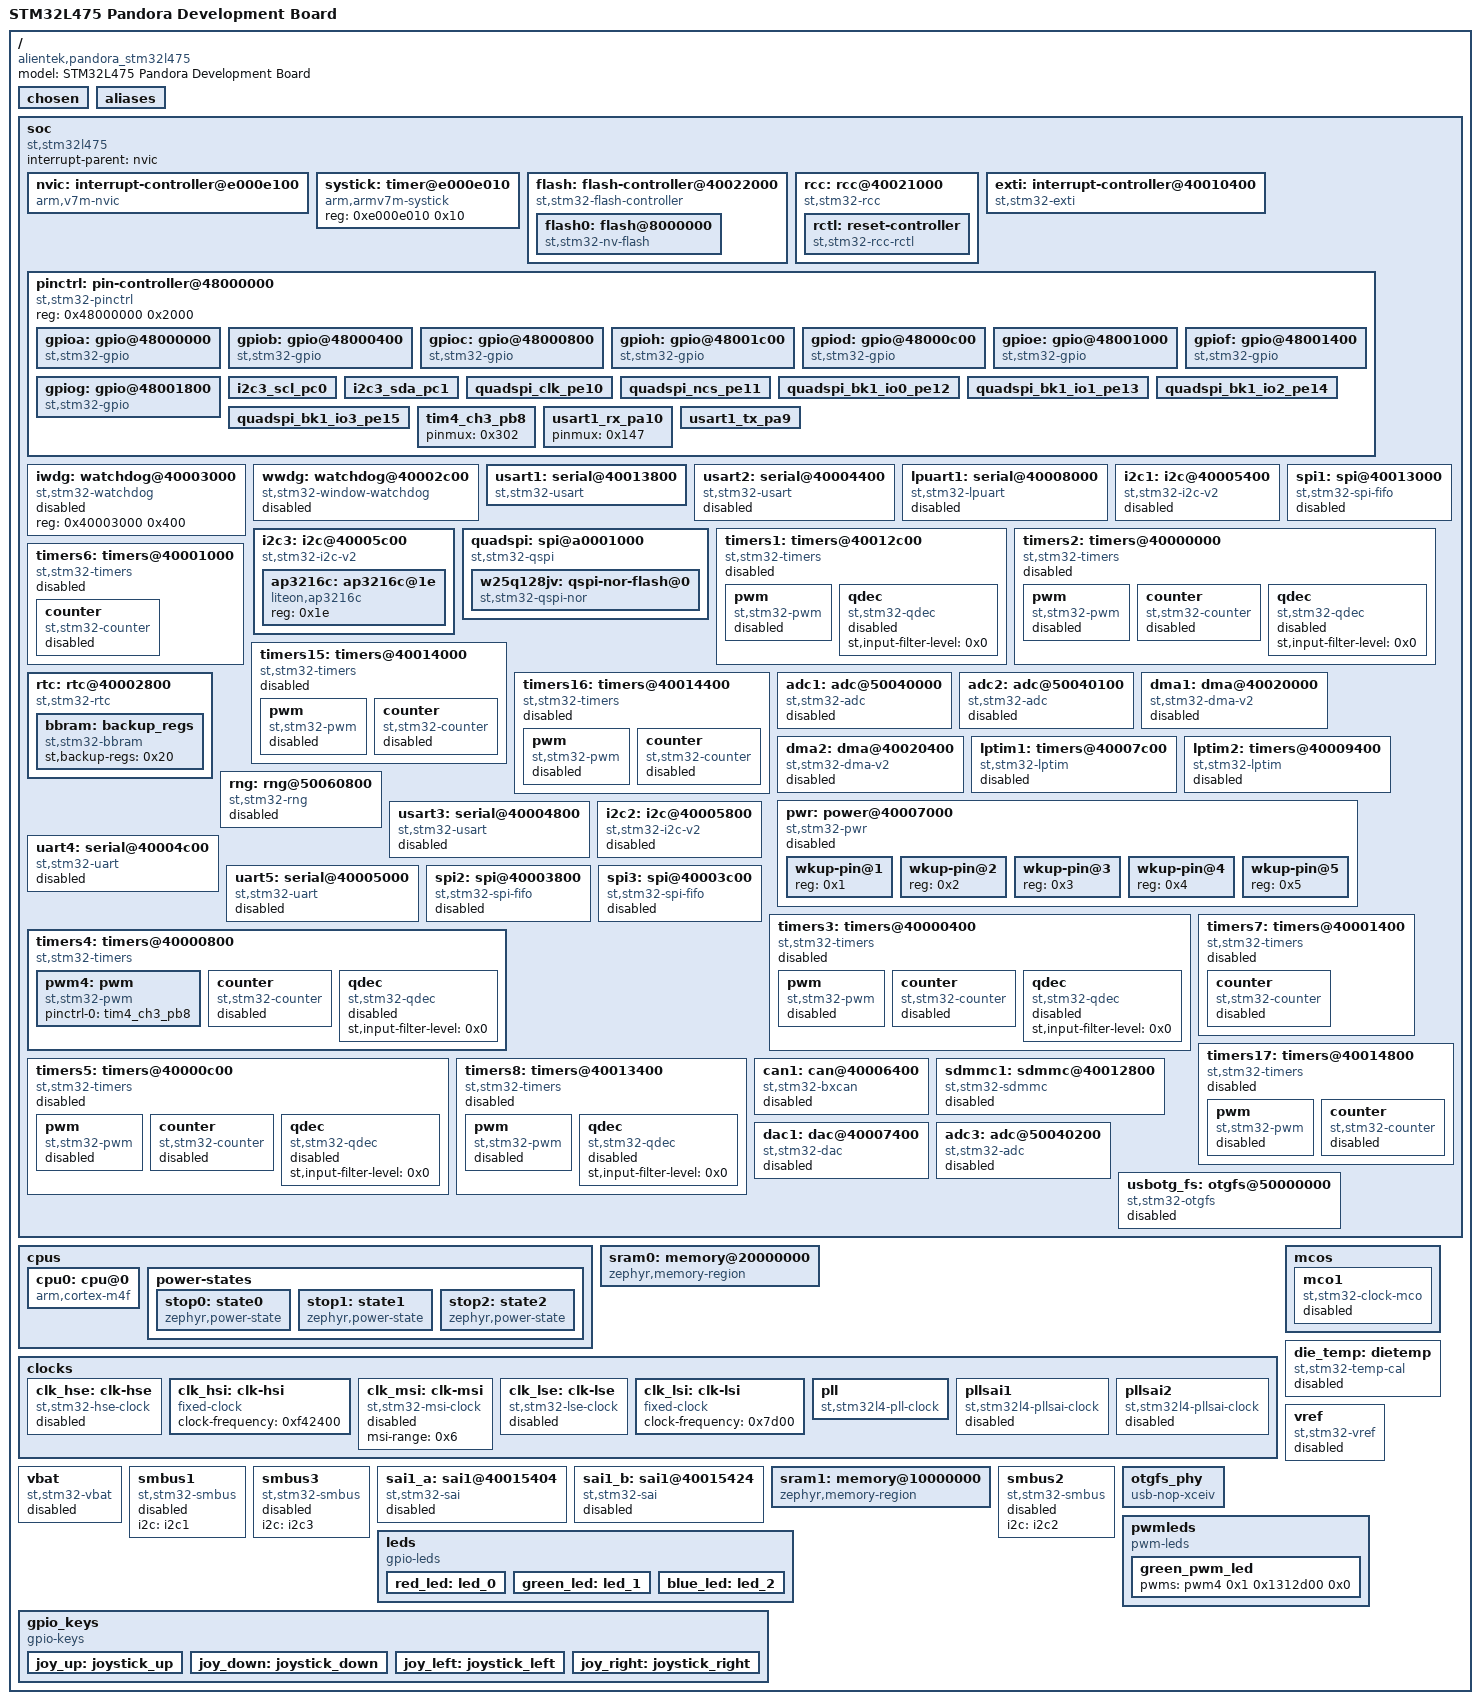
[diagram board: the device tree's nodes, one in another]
/dts-v1/;

/* node '/' defined in zephyr\dts\common\skeleton.dtsi:9 */
/ {
	#address-cells = < 0x1 >;                      /* in zephyr\dts\common\skeleton.dtsi:10 */
	#size-cells = < 0x1 >;                         /* in zephyr\dts\common\skeleton.dtsi:11 */
	model = "STM32L475 Pandora Development Board"; /* in zephyr\boards\alientek\pandora_stm32l475\pandora_stm32l475.dts:17 */
	compatible = "alientek,pandora_stm32l475";     /* in zephyr\boards\alientek\pandora_stm32l475\pandora_stm32l475.dts:18 */

	/* node '/chosen' defined in zephyr\dts\common\skeleton.dtsi:13 */
	chosen {
		zephyr,entropy = &rng;            /* in zephyr\dts\arm\st\l4\stm32l4.dtsi:27 */
		zephyr,flash-controller = &flash; /* in zephyr\dts\arm\st\l4\stm32l4.dtsi:28 */
		zephyr,console = &usart1;         /* in zephyr\boards\alientek\pandora_stm32l475\pandora_stm32l475.dts:26 */
		zephyr,shell-uart = &usart1;      /* in zephyr\boards\alientek\pandora_stm32l475\pandora_stm32l475.dts:27 */
		zephyr,sram = &sram0;             /* in zephyr\boards\alientek\pandora_stm32l475\pandora_stm32l475.dts:28 */
		zephyr,flash = &flash0;           /* in zephyr\boards\alientek\pandora_stm32l475\pandora_stm32l475.dts:29 */
	};

	/* node '/aliases' defined in zephyr\dts\common\skeleton.dtsi:15 */
	aliases {
		led0 = &red_led;           /* in zephyr\boards\alientek\pandora_stm32l475\pandora_stm32l475.dts:21 */
		sw0 = &joy_up;             /* in zephyr\boards\alientek\pandora_stm32l475\pandora_stm32l475.dts:22 */
		pwm-led0 = &green_pwm_led; /* in application\pandora_stm32l475.overlay:14 */
		led1 = &green_led;         /* in application\pandora_stm32l475.overlay:15 */
		ap3216c-i2c = &ap3216c;    /* in application\pandora_stm32l475.overlay:16 */
	};

	/* node '/soc' defined in zephyr\dts\arm\armv7-m.dtsi:6 */
	soc {
		#address-cells = < 0x1 >;     /* in zephyr\dts\arm\armv7-m.dtsi:7 */
		#size-cells = < 0x1 >;        /* in zephyr\dts\arm\armv7-m.dtsi:8 */
		interrupt-parent = < &nvic >; /* in zephyr\dts\arm\armv7-m.dtsi:10 */
		ranges;                       /* in zephyr\dts\arm\armv7-m.dtsi:11 */
		compatible = "st,stm32l475",
		             "st,stm32l4",
		             "simple-bus";    /* in zephyr\dts\arm\st\l4\stm32l475.dtsi:11 */

		/* node '/soc/interrupt-controller@e000e100' defined in zephyr\dts\arm\armv7-m.dtsi:13 */
		nvic: interrupt-controller@e000e100 {
			#address-cells = < 0x1 >;            /* in zephyr\dts\arm\armv7-m.dtsi:14 */
			compatible = "arm,v7m-nvic";         /* in zephyr\dts\arm\armv7-m.dtsi:15 */
			reg = < 0xe000e100 0xc00 >;          /* in zephyr\dts\arm\armv7-m.dtsi:16 */
			interrupt-controller;                /* in zephyr\dts\arm\armv7-m.dtsi:17 */
			#interrupt-cells = < 0x2 >;          /* in zephyr\dts\arm\armv7-m.dtsi:18 */
			arm,num-irq-priority-bits = < 0x4 >; /* in zephyr\dts\arm\st\l4\stm32l4.dtsi:619 */
			phandle = < 0x1 >;                   /* in zephyr\dts\arm\armv7-m.dtsi:10 */
		};

		/* node '/soc/timer@e000e010' defined in zephyr\dts\arm\armv7-m.dtsi:21 */
		systick: timer@e000e010 {
			compatible = "arm,armv7m-systick"; /* in zephyr\dts\arm\armv7-m.dtsi:22 */
			reg = < 0xe000e010 0x10 >;         /* in zephyr\dts\arm\armv7-m.dtsi:23 */
		};

		/* node '/soc/flash-controller@40022000' defined in zephyr\dts\arm\st\l4\stm32l4.dtsi:128 */
		flash: flash-controller@40022000 {
			compatible = "st,stm32-flash-controller",
			             "st,stm32l4-flash-controller"; /* in zephyr\dts\arm\st\l4\stm32l4.dtsi:129 */
			reg = < 0x40022000 0x400 >;                 /* in zephyr\dts\arm\st\l4\stm32l4.dtsi:130 */
			interrupts = < 0x4 0x0 >;                   /* in zephyr\dts\arm\st\l4\stm32l4.dtsi:131 */
			clocks = < &rcc 0x48 0x100 >;               /* in zephyr\dts\arm\st\l4\stm32l4.dtsi:132 */
			#address-cells = < 0x1 >;                   /* in zephyr\dts\arm\st\l4\stm32l4.dtsi:134 */
			#size-cells = < 0x1 >;                      /* in zephyr\dts\arm\st\l4\stm32l4.dtsi:135 */

			/* node '/soc/flash-controller@40022000/flash@8000000' defined in zephyr\dts\arm\st\l4\stm32l4.dtsi:137 */
			flash0: flash@8000000 {
				compatible = "st,stm32-nv-flash",
				             "soc-nv-flash";      /* in zephyr\dts\arm\st\l4\stm32l4.dtsi:138 */
				write-block-size = < 0x8 >;       /* in zephyr\dts\arm\st\l4\stm32l4.dtsi:140 */
				erase-block-size = < 0x800 >;     /* in zephyr\dts\arm\st\l4\stm32l4.dtsi:141 */
				max-erase-time = < 0x19 >;        /* in zephyr\dts\arm\st\l4\stm32l4.dtsi:143 */
				reg = < 0x8000000 0x80000 >;      /* in zephyr\dts\arm\st\l4\stm32l475Xe.dtsi:20 */
			};
		};

		/* node '/soc/rcc@40021000' defined in zephyr\dts\arm\st\l4\stm32l4.dtsi:147 */
		rcc: rcc@40021000 {
			compatible = "st,stm32-rcc";     /* in zephyr\dts\arm\st\l4\stm32l4.dtsi:148 */
			#clock-cells = < 0x2 >;          /* in zephyr\dts\arm\st\l4\stm32l4.dtsi:149 */
			reg = < 0x40021000 0x400 >;      /* in zephyr\dts\arm\st\l4\stm32l4.dtsi:150 */
			clocks = < &pll >;               /* in zephyr\boards\alientek\pandora_stm32l475\pandora_stm32l475.dts:119 */
			clock-frequency = < 0x4c4b400 >; /* in zephyr\boards\alientek\pandora_stm32l475\pandora_stm32l475.dts:120 */
			ahb-prescaler = < 0x1 >;         /* in zephyr\boards\alientek\pandora_stm32l475\pandora_stm32l475.dts:121 */
			apb1-prescaler = < 0x1 >;        /* in zephyr\boards\alientek\pandora_stm32l475\pandora_stm32l475.dts:122 */
			apb2-prescaler = < 0x1 >;        /* in zephyr\boards\alientek\pandora_stm32l475\pandora_stm32l475.dts:123 */
			phandle = < 0x2 >;               /* in zephyr\dts\arm\st\l4\stm32l4.dtsi:132 */

			/* node '/soc/rcc@40021000/reset-controller' defined in zephyr\dts\arm\st\l4\stm32l4.dtsi:152 */
			rctl: reset-controller {
				compatible = "st,stm32-rcc-rctl"; /* in zephyr\dts\arm\st\l4\stm32l4.dtsi:153 */
				#reset-cells = < 0x1 >;           /* in zephyr\dts\arm\st\l4\stm32l4.dtsi:154 */
				phandle = < 0x4 >;                /* in zephyr\dts\arm\st\l4\stm32l4.dtsi:231 */
			};
		};

		/* node '/soc/interrupt-controller@40010400' defined in zephyr\dts\arm\st\l4\stm32l4.dtsi:158 */
		exti: interrupt-controller@40010400 {
			compatible = "st,stm32-exti";  /* in zephyr\dts\arm\st\l4\stm32l4.dtsi:159 */
			interrupt-controller;          /* in zephyr\dts\arm\st\l4\stm32l4.dtsi:160 */
			#interrupt-cells = < 0x1 >;    /* in zephyr\dts\arm\st\l4\stm32l4.dtsi:161 */
			#address-cells = < 0x0 >;      /* in zephyr\dts\arm\st\l4\stm32l4.dtsi:162 */
			reg = < 0x40010400 0x400 >;    /* in zephyr\dts\arm\st\l4\stm32l4.dtsi:163 */
			clocks = < &rcc 0x60 0x1 >;    /* in zephyr\dts\arm\st\l4\stm32l4.dtsi:164 */
			num-lines = < 0x40 >;          /* in zephyr\dts\arm\st\l4\stm32l4.dtsi:165 */
			interrupts = < 0x6 0x0 >,
			             < 0x7 0x0 >,
			             < 0x8 0x0 >,
			             < 0x9 0x0 >,
			             < 0xa 0x0 >,
			             < 0x17 0x0 >,
			             < 0x28 0x0 >;     /* in zephyr\dts\arm\st\l4\stm32l4.dtsi:166 */
			interrupt-names = "line0",
			                  "line1",
			                  "line2",
			                  "line3",
			                  "line4",
			                  "line5-9",
			                  "line10-15"; /* in zephyr\dts\arm\st\l4\stm32l4.dtsi:168 */
			line-ranges = < 0x0 0x1 >,
			              < 0x1 0x1 >,
			              < 0x2 0x1 >,
			              < 0x3 0x1 >,
			              < 0x4 0x1 >,
			              < 0x5 0x5 >,
			              < 0xa 0x6 >;     /* in zephyr\dts\arm\st\l4\stm32l4.dtsi:170 */
		};

		/* node '/soc/pin-controller@48000000' defined in zephyr\dts\arm\st\l4\stm32l4.dtsi:174 */
		pinctrl: pin-controller@48000000 {
			compatible = "st,stm32-pinctrl"; /* in zephyr\dts\arm\st\l4\stm32l4.dtsi:175 */
			#address-cells = < 0x1 >;        /* in zephyr\dts\arm\st\l4\stm32l4.dtsi:176 */
			#size-cells = < 0x1 >;           /* in zephyr\dts\arm\st\l4\stm32l4.dtsi:177 */
			reg = < 0x48000000 0x2000 >;     /* in zephyr\dts\arm\st\l4\stm32l4.dtsi:178 */

			/* node '/soc/pin-controller@48000000/gpio@48000000' defined in zephyr\dts\arm\st\l4\stm32l4.dtsi:180 */
			gpioa: gpio@48000000 {
				compatible = "st,stm32-gpio"; /* in zephyr\dts\arm\st\l4\stm32l4.dtsi:181 */
				gpio-controller;              /* in zephyr\dts\arm\st\l4\stm32l4.dtsi:182 */
				#gpio-cells = < 0x2 >;        /* in zephyr\dts\arm\st\l4\stm32l4.dtsi:183 */
				reg = < 0x48000000 0x400 >;   /* in zephyr\dts\arm\st\l4\stm32l4.dtsi:184 */
				clocks = < &rcc 0x4c 0x1 >;   /* in zephyr\dts\arm\st\l4\stm32l4.dtsi:185 */
			};

			/* node '/soc/pin-controller@48000000/gpio@48000400' defined in zephyr\dts\arm\st\l4\stm32l4.dtsi:188 */
			gpiob: gpio@48000400 {
				compatible = "st,stm32-gpio"; /* in zephyr\dts\arm\st\l4\stm32l4.dtsi:189 */
				gpio-controller;              /* in zephyr\dts\arm\st\l4\stm32l4.dtsi:190 */
				#gpio-cells = < 0x2 >;        /* in zephyr\dts\arm\st\l4\stm32l4.dtsi:191 */
				reg = < 0x48000400 0x400 >;   /* in zephyr\dts\arm\st\l4\stm32l4.dtsi:192 */
				clocks = < &rcc 0x4c 0x2 >;   /* in zephyr\dts\arm\st\l4\stm32l4.dtsi:193 */
			};

			/* node '/soc/pin-controller@48000000/gpio@48000800' defined in zephyr\dts\arm\st\l4\stm32l4.dtsi:196 */
			gpioc: gpio@48000800 {
				compatible = "st,stm32-gpio"; /* in zephyr\dts\arm\st\l4\stm32l4.dtsi:197 */
				gpio-controller;              /* in zephyr\dts\arm\st\l4\stm32l4.dtsi:198 */
				#gpio-cells = < 0x2 >;        /* in zephyr\dts\arm\st\l4\stm32l4.dtsi:199 */
				reg = < 0x48000800 0x400 >;   /* in zephyr\dts\arm\st\l4\stm32l4.dtsi:200 */
				clocks = < &rcc 0x4c 0x4 >;   /* in zephyr\dts\arm\st\l4\stm32l4.dtsi:201 */
				phandle = < 0x1b >;           /* in zephyr\boards\alientek\pandora_stm32l475\pandora_stm32l475.dts:56 */
			};

			/* node '/soc/pin-controller@48000000/gpio@48001c00' defined in zephyr\dts\arm\st\l4\stm32l4.dtsi:204 */
			gpioh: gpio@48001c00 {
				compatible = "st,stm32-gpio"; /* in zephyr\dts\arm\st\l4\stm32l4.dtsi:205 */
				gpio-controller;              /* in zephyr\dts\arm\st\l4\stm32l4.dtsi:206 */
				#gpio-cells = < 0x2 >;        /* in zephyr\dts\arm\st\l4\stm32l4.dtsi:207 */
				reg = < 0x48001c00 0x400 >;   /* in zephyr\dts\arm\st\l4\stm32l4.dtsi:208 */
				clocks = < &rcc 0x4c 0x80 >;  /* in zephyr\dts\arm\st\l4\stm32l4.dtsi:209 */
			};

			/* node '/soc/pin-controller@48000000/gpio@48000c00' defined in zephyr\dts\arm\st\l4\stm32l471.dtsi:28 */
			gpiod: gpio@48000c00 {
				compatible = "st,stm32-gpio"; /* in zephyr\dts\arm\st\l4\stm32l471.dtsi:29 */
				gpio-controller;              /* in zephyr\dts\arm\st\l4\stm32l471.dtsi:30 */
				#gpio-cells = < 0x2 >;        /* in zephyr\dts\arm\st\l4\stm32l471.dtsi:31 */
				reg = < 0x48000c00 0x400 >;   /* in zephyr\dts\arm\st\l4\stm32l471.dtsi:32 */
				clocks = < &rcc 0x4c 0x8 >;   /* in zephyr\dts\arm\st\l4\stm32l471.dtsi:33 */
				phandle = < 0x1c >;           /* in zephyr\boards\alientek\pandora_stm32l475\pandora_stm32l475.dts:62 */
			};

			/* node '/soc/pin-controller@48000000/gpio@48001000' defined in zephyr\dts\arm\st\l4\stm32l471.dtsi:36 */
			gpioe: gpio@48001000 {
				compatible = "st,stm32-gpio"; /* in zephyr\dts\arm\st\l4\stm32l471.dtsi:37 */
				gpio-controller;              /* in zephyr\dts\arm\st\l4\stm32l471.dtsi:38 */
				#gpio-cells = < 0x2 >;        /* in zephyr\dts\arm\st\l4\stm32l471.dtsi:39 */
				reg = < 0x48001000 0x400 >;   /* in zephyr\dts\arm\st\l4\stm32l471.dtsi:40 */
				clocks = < &rcc 0x4c 0x10 >;  /* in zephyr\dts\arm\st\l4\stm32l471.dtsi:41 */
				phandle = < 0x1a >;           /* in application\pandora_stm32l475.overlay:30 */
			};

			/* node '/soc/pin-controller@48000000/gpio@48001400' defined in zephyr\dts\arm\st\l4\stm32l471.dtsi:44 */
			gpiof: gpio@48001400 {
				compatible = "st,stm32-gpio"; /* in zephyr\dts\arm\st\l4\stm32l471.dtsi:45 */
				gpio-controller;              /* in zephyr\dts\arm\st\l4\stm32l471.dtsi:46 */
				#gpio-cells = < 0x2 >;        /* in zephyr\dts\arm\st\l4\stm32l471.dtsi:47 */
				reg = < 0x48001400 0x400 >;   /* in zephyr\dts\arm\st\l4\stm32l471.dtsi:48 */
				clocks = < &rcc 0x4c 0x20 >;  /* in zephyr\dts\arm\st\l4\stm32l471.dtsi:49 */
			};

			/* node '/soc/pin-controller@48000000/gpio@48001800' defined in zephyr\dts\arm\st\l4\stm32l471.dtsi:52 */
			gpiog: gpio@48001800 {
				compatible = "st,stm32-gpio"; /* in zephyr\dts\arm\st\l4\stm32l471.dtsi:53 */
				gpio-controller;              /* in zephyr\dts\arm\st\l4\stm32l471.dtsi:54 */
				#gpio-cells = < 0x2 >;        /* in zephyr\dts\arm\st\l4\stm32l471.dtsi:55 */
				reg = < 0x48001800 0x400 >;   /* in zephyr\dts\arm\st\l4\stm32l471.dtsi:56 */
				clocks = < &rcc 0x4c 0x40 >;  /* in zephyr\dts\arm\st\l4\stm32l471.dtsi:57 */
			};

			/* node '/soc/pin-controller@48000000/i2c3_scl_pc0' defined in modules\hal\stm32\dts\st\l4\stm32l475v(c-e-g)tx-pinctrl.dtsi:976 */
			i2c3_scl_pc0: i2c3_scl_pc0 {
				pinmux = < 0x404 >; /* in modules\hal\stm32\dts\st\l4\stm32l475v(c-e-g)tx-pinctrl.dtsi:977 */
				bias-pull-up;       /* in modules\hal\stm32\dts\st\l4\stm32l475v(c-e-g)tx-pinctrl.dtsi:978 */
				drive-open-drain;   /* in modules\hal\stm32\dts\st\l4\stm32l475v(c-e-g)tx-pinctrl.dtsi:979 */
				phandle = < 0x7 >;  /* in application\pandora_stm32l475.overlay:45 */
			};

			/* node '/soc/pin-controller@48000000/i2c3_sda_pc1' defined in modules\hal\stm32\dts\st\l4\stm32l475v(c-e-g)tx-pinctrl.dtsi:1008 */
			i2c3_sda_pc1: i2c3_sda_pc1 {
				pinmux = < 0x424 >; /* in modules\hal\stm32\dts\st\l4\stm32l475v(c-e-g)tx-pinctrl.dtsi:1009 */
				bias-pull-up;       /* in modules\hal\stm32\dts\st\l4\stm32l475v(c-e-g)tx-pinctrl.dtsi:1010 */
				drive-open-drain;   /* in modules\hal\stm32\dts\st\l4\stm32l475v(c-e-g)tx-pinctrl.dtsi:1011 */
				phandle = < 0x8 >;  /* in application\pandora_stm32l475.overlay:45 */
			};

			/* node '/soc/pin-controller@48000000/quadspi_clk_pe10' defined in modules\hal\stm32\dts\st\l4\stm32l475v(c-e-g)tx-pinctrl.dtsi:1111 */
			quadspi_clk_pe10: quadspi_clk_pe10 {
				pinmux = < 0x94a >;            /* in modules\hal\stm32\dts\st\l4\stm32l475v(c-e-g)tx-pinctrl.dtsi:1112 */
				slew-rate = "very-high-speed"; /* in modules\hal\stm32\dts\st\l4\stm32l475v(c-e-g)tx-pinctrl.dtsi:1113 */
				phandle = < 0x9 >;             /* in zephyr\boards\alientek\pandora_stm32l475\pandora_stm32l475.dts:81 */
			};

			/* node '/soc/pin-controller@48000000/quadspi_ncs_pe11' defined in modules\hal\stm32\dts\st\l4\stm32l475v(c-e-g)tx-pinctrl.dtsi:1116 */
			quadspi_ncs_pe11: quadspi_ncs_pe11 {
				pinmux = < 0x96a >;            /* in modules\hal\stm32\dts\st\l4\stm32l475v(c-e-g)tx-pinctrl.dtsi:1117 */
				slew-rate = "very-high-speed"; /* in modules\hal\stm32\dts\st\l4\stm32l475v(c-e-g)tx-pinctrl.dtsi:1118 */
				phandle = < 0xa >;             /* in zephyr\boards\alientek\pandora_stm32l475\pandora_stm32l475.dts:81 */
			};

			/* node '/soc/pin-controller@48000000/quadspi_bk1_io0_pe12' defined in modules\hal\stm32\dts\st\l4\stm32l475v(c-e-g)tx-pinctrl.dtsi:1121 */
			quadspi_bk1_io0_pe12: quadspi_bk1_io0_pe12 {
				pinmux = < 0x98a >;            /* in modules\hal\stm32\dts\st\l4\stm32l475v(c-e-g)tx-pinctrl.dtsi:1122 */
				slew-rate = "very-high-speed"; /* in modules\hal\stm32\dts\st\l4\stm32l475v(c-e-g)tx-pinctrl.dtsi:1123 */
				phandle = < 0xb >;             /* in zephyr\boards\alientek\pandora_stm32l475\pandora_stm32l475.dts:81 */
			};

			/* node '/soc/pin-controller@48000000/quadspi_bk1_io1_pe13' defined in modules\hal\stm32\dts\st\l4\stm32l475v(c-e-g)tx-pinctrl.dtsi:1126 */
			quadspi_bk1_io1_pe13: quadspi_bk1_io1_pe13 {
				pinmux = < 0x9aa >;            /* in modules\hal\stm32\dts\st\l4\stm32l475v(c-e-g)tx-pinctrl.dtsi:1127 */
				slew-rate = "very-high-speed"; /* in modules\hal\stm32\dts\st\l4\stm32l475v(c-e-g)tx-pinctrl.dtsi:1128 */
				phandle = < 0xc >;             /* in zephyr\boards\alientek\pandora_stm32l475\pandora_stm32l475.dts:81 */
			};

			/* node '/soc/pin-controller@48000000/quadspi_bk1_io2_pe14' defined in modules\hal\stm32\dts\st\l4\stm32l475v(c-e-g)tx-pinctrl.dtsi:1131 */
			quadspi_bk1_io2_pe14: quadspi_bk1_io2_pe14 {
				pinmux = < 0x9ca >;            /* in modules\hal\stm32\dts\st\l4\stm32l475v(c-e-g)tx-pinctrl.dtsi:1132 */
				slew-rate = "very-high-speed"; /* in modules\hal\stm32\dts\st\l4\stm32l475v(c-e-g)tx-pinctrl.dtsi:1133 */
				phandle = < 0xd >;             /* in zephyr\boards\alientek\pandora_stm32l475\pandora_stm32l475.dts:81 */
			};

			/* node '/soc/pin-controller@48000000/quadspi_bk1_io3_pe15' defined in modules\hal\stm32\dts\st\l4\stm32l475v(c-e-g)tx-pinctrl.dtsi:1136 */
			quadspi_bk1_io3_pe15: quadspi_bk1_io3_pe15 {
				pinmux = < 0x9ea >;            /* in modules\hal\stm32\dts\st\l4\stm32l475v(c-e-g)tx-pinctrl.dtsi:1137 */
				slew-rate = "very-high-speed"; /* in modules\hal\stm32\dts\st\l4\stm32l475v(c-e-g)tx-pinctrl.dtsi:1138 */
				phandle = < 0xe >;             /* in zephyr\boards\alientek\pandora_stm32l475\pandora_stm32l475.dts:81 */
			};

			/* node '/soc/pin-controller@48000000/tim4_ch3_pb8' defined in modules\hal\stm32\dts\st\l4\stm32l475v(c-e-g)tx-pinctrl.dtsi:1760 */
			tim4_ch3_pb8: tim4_ch3_pb8 {
				pinmux = < 0x302 >; /* in application\pandora_stm32l475.overlay:72 */
				phandle = < 0xf >;  /* in application\pandora_stm32l475.overlay:64 */
			};

			/* node '/soc/pin-controller@48000000/usart1_rx_pa10' defined in modules\hal\stm32\dts\st\l4\stm32l475v(c-e-g)tx-pinctrl.dtsi:2182 */
			usart1_rx_pa10: usart1_rx_pa10 {
				pinmux = < 0x147 >; /* in modules\hal\stm32\dts\st\l4\stm32l475v(c-e-g)tx-pinctrl.dtsi:2183 */
				phandle = < 0x6 >;  /* in zephyr\boards\alientek\pandora_stm32l475\pandora_stm32l475.dts:127 */
			};

			/* node '/soc/pin-controller@48000000/usart1_tx_pa9' defined in modules\hal\stm32\dts\st\l4\stm32l475v(c-e-g)tx-pinctrl.dtsi:2236 */
			usart1_tx_pa9: usart1_tx_pa9 {
				pinmux = < 0x127 >; /* in modules\hal\stm32\dts\st\l4\stm32l475v(c-e-g)tx-pinctrl.dtsi:2237 */
				bias-pull-up;       /* in modules\hal\stm32\dts\st\l4\stm32l475v(c-e-g)tx-pinctrl.dtsi:2238 */
				phandle = < 0x5 >;  /* in zephyr\boards\alientek\pandora_stm32l475\pandora_stm32l475.dts:127 */
			};
		};

		/* node '/soc/watchdog@40003000' defined in zephyr\dts\arm\st\l4\stm32l4.dtsi:213 */
		iwdg: watchdog@40003000 {
			compatible = "st,stm32-watchdog"; /* in zephyr\dts\arm\st\l4\stm32l4.dtsi:214 */
			reg = < 0x40003000 0x400 >;       /* in zephyr\dts\arm\st\l4\stm32l4.dtsi:215 */
			status = "disabled";              /* in zephyr\dts\arm\st\l4\stm32l4.dtsi:216 */
		};

		/* node '/soc/watchdog@40002c00' defined in zephyr\dts\arm\st\l4\stm32l4.dtsi:219 */
		wwdg: watchdog@40002c00 {
			compatible = "st,stm32-window-watchdog"; /* in zephyr\dts\arm\st\l4\stm32l4.dtsi:220 */
			reg = < 0x40002c00 0x400 >;              /* in zephyr\dts\arm\st\l4\stm32l4.dtsi:221 */
			clocks = < &rcc 0x58 0x800 >;            /* in zephyr\dts\arm\st\l4\stm32l4.dtsi:222 */
			interrupts = < 0x0 0x7 >;                /* in zephyr\dts\arm\st\l4\stm32l4.dtsi:223 */
			status = "disabled";                     /* in zephyr\dts\arm\st\l4\stm32l4.dtsi:224 */
		};

		/* node '/soc/serial@40013800' defined in zephyr\dts\arm\st\l4\stm32l4.dtsi:227 */
		usart1: serial@40013800 {
			compatible = "st,stm32-usart",
			             "st,stm32-uart";                   /* in zephyr\dts\arm\st\l4\stm32l4.dtsi:228 */
			reg = < 0x40013800 0x400 >;                     /* in zephyr\dts\arm\st\l4\stm32l4.dtsi:229 */
			clocks = < &rcc 0x60 0x4000 >;                  /* in zephyr\dts\arm\st\l4\stm32l4.dtsi:230 */
			resets = < &rctl 0x80e >;                       /* in zephyr\dts\arm\st\l4\stm32l4.dtsi:231 */
			interrupts = < 0x25 0x0 >;                      /* in zephyr\dts\arm\st\l4\stm32l4.dtsi:232 */
			pinctrl-0 = < &usart1_tx_pa9 &usart1_rx_pa10 >; /* in zephyr\boards\alientek\pandora_stm32l475\pandora_stm32l475.dts:127 */
			pinctrl-names = "default";                      /* in zephyr\boards\alientek\pandora_stm32l475\pandora_stm32l475.dts:128 */
			current-speed = < 0x1c200 >;                    /* in zephyr\boards\alientek\pandora_stm32l475\pandora_stm32l475.dts:129 */
			status = "okay";                                /* in zephyr\boards\alientek\pandora_stm32l475\pandora_stm32l475.dts:130 */
		};

		/* node '/soc/serial@40004400' defined in zephyr\dts\arm\st\l4\stm32l4.dtsi:236 */
		usart2: serial@40004400 {
			compatible = "st,stm32-usart",
			             "st,stm32-uart";   /* in zephyr\dts\arm\st\l4\stm32l4.dtsi:237 */
			reg = < 0x40004400 0x400 >;     /* in zephyr\dts\arm\st\l4\stm32l4.dtsi:238 */
			clocks = < &rcc 0x58 0x20000 >; /* in zephyr\dts\arm\st\l4\stm32l4.dtsi:239 */
			resets = < &rctl 0x711 >;       /* in zephyr\dts\arm\st\l4\stm32l4.dtsi:240 */
			interrupts = < 0x26 0x0 >;      /* in zephyr\dts\arm\st\l4\stm32l4.dtsi:241 */
			status = "disabled";            /* in zephyr\dts\arm\st\l4\stm32l4.dtsi:242 */
		};

		/* node '/soc/serial@40008000' defined in zephyr\dts\arm\st\l4\stm32l4.dtsi:245 */
		lpuart1: serial@40008000 {
			compatible = "st,stm32-lpuart",
			             "st,stm32-uart";   /* in zephyr\dts\arm\st\l4\stm32l4.dtsi:246 */
			reg = < 0x40008000 0x400 >;     /* in zephyr\dts\arm\st\l4\stm32l4.dtsi:247 */
			clocks = < &rcc 0x5c 0x1 >;     /* in zephyr\dts\arm\st\l4\stm32l4.dtsi:248 */
			resets = < &rctl 0x780 >;       /* in zephyr\dts\arm\st\l4\stm32l4.dtsi:249 */
			interrupts = < 0x46 0x0 >;      /* in zephyr\dts\arm\st\l4\stm32l4.dtsi:250 */
			status = "disabled";            /* in zephyr\dts\arm\st\l4\stm32l4.dtsi:251 */
		};

		/* node '/soc/i2c@40005400' defined in zephyr\dts\arm\st\l4\stm32l4.dtsi:254 */
		i2c1: i2c@40005400 {
			compatible = "st,stm32-i2c-v2";  /* in zephyr\dts\arm\st\l4\stm32l4.dtsi:255 */
			clock-frequency = < 0x186a0 >;   /* in zephyr\dts\arm\st\l4\stm32l4.dtsi:256 */
			#address-cells = < 0x1 >;        /* in zephyr\dts\arm\st\l4\stm32l4.dtsi:257 */
			#size-cells = < 0x0 >;           /* in zephyr\dts\arm\st\l4\stm32l4.dtsi:258 */
			reg = < 0x40005400 0x400 >;      /* in zephyr\dts\arm\st\l4\stm32l4.dtsi:259 */
			clocks = < &rcc 0x58 0x200000 >; /* in zephyr\dts\arm\st\l4\stm32l4.dtsi:260 */
			interrupts = < 0x1f 0x0 >,
			             < 0x20 0x0 >;       /* in zephyr\dts\arm\st\l4\stm32l4.dtsi:261 */
			interrupt-names = "event",
			                  "error";       /* in zephyr\dts\arm\st\l4\stm32l4.dtsi:262 */
			status = "disabled";             /* in zephyr\dts\arm\st\l4\stm32l4.dtsi:263 */
			phandle = < 0x16 >;              /* in zephyr\dts\arm\st\l4\stm32l4.dtsi:581 */
		};

		/* node '/soc/i2c@40005c00' defined in zephyr\dts\arm\st\l4\stm32l4.dtsi:266 */
		i2c3: i2c@40005c00 {
			compatible = "st,stm32-i2c-v2";              /* in zephyr\dts\arm\st\l4\stm32l4.dtsi:267 */
			#address-cells = < 0x1 >;                    /* in zephyr\dts\arm\st\l4\stm32l4.dtsi:269 */
			#size-cells = < 0x0 >;                       /* in zephyr\dts\arm\st\l4\stm32l4.dtsi:270 */
			reg = < 0x40005c00 0x400 >;                  /* in zephyr\dts\arm\st\l4\stm32l4.dtsi:271 */
			clocks = < &rcc 0x58 0x800000 >;             /* in zephyr\dts\arm\st\l4\stm32l4.dtsi:272 */
			interrupts = < 0x48 0x0 >,
			             < 0x49 0x0 >;                   /* in zephyr\dts\arm\st\l4\stm32l4.dtsi:273 */
			interrupt-names = "event",
			                  "error";                   /* in zephyr\dts\arm\st\l4\stm32l4.dtsi:274 */
			status = "okay";                             /* in application\pandora_stm32l475.overlay:44 */
			pinctrl-0 = < &i2c3_scl_pc0 &i2c3_sda_pc1 >; /* in application\pandora_stm32l475.overlay:45 */
			pinctrl-names = "default";                   /* in application\pandora_stm32l475.overlay:46 */
			clock-frequency = < 0x186a0 >;               /* in application\pandora_stm32l475.overlay:47 */
			phandle = < 0x17 >;                          /* in zephyr\dts\arm\st\l4\stm32l4.dtsi:589 */

			/* node '/soc/i2c@40005c00/ap3216c@1e' defined in application\pandora_stm32l475.overlay:49 */
			ap3216c: ap3216c@1e {
				compatible = "liteon,ap3216c"; /* in application\pandora_stm32l475.overlay:50 */
				reg = < 0x1e >;                /* in application\pandora_stm32l475.overlay:51 */
				status = "okay";               /* in application\pandora_stm32l475.overlay:52 */
			};
		};

		/* node '/soc/spi@a0001000' defined in zephyr\dts\arm\st\l4\stm32l4.dtsi:278 */
		quadspi: spi@a0001000 {
			compatible = "st,stm32-qspi";                                                                                       /* in zephyr\dts\arm\st\l4\stm32l4.dtsi:279 */
			#address-cells = < 0x1 >;                                                                                           /* in zephyr\dts\arm\st\l4\stm32l4.dtsi:280 */
			#size-cells = < 0x0 >;                                                                                              /* in zephyr\dts\arm\st\l4\stm32l4.dtsi:281 */
			reg = < 0xa0001000 0x400 >,
			      < 0x90000000 0x10000000 >;                                                                                    /* in zephyr\dts\arm\st\l4\stm32l4.dtsi:282 */
			interrupts = < 0x47 0x0 >;                                                                                          /* in zephyr\dts\arm\st\l4\stm32l4.dtsi:283 */
			clocks = < &rcc 0x50 0x100 >;                                                                                       /* in zephyr\dts\arm\st\l4\stm32l4.dtsi:284 */
			pinctrl-0 = < &quadspi_clk_pe10 &quadspi_ncs_pe11 &quadspi_bk1_io0_pe12 &quadspi_bk1_io1_pe13 &quadspi_bk1_io2_pe14
			              &quadspi_bk1_io3_pe15 >;                                                                              /* in zephyr\boards\alientek\pandora_stm32l475\pandora_stm32l475.dts:81 */
			pinctrl-names = "default";                                                                                          /* in zephyr\boards\alientek\pandora_stm32l475\pandora_stm32l475.dts:84 */
			status = "okay";                                                                                                    /* in zephyr\boards\alientek\pandora_stm32l475\pandora_stm32l475.dts:85 */

			/* node '/soc/spi@a0001000/qspi-nor-flash@0' defined in zephyr\boards\alientek\pandora_stm32l475\pandora_stm32l475.dts:87 */
			w25q128jv: qspi-nor-flash@0 {
				compatible = "st,stm32-qspi-nor";   /* in zephyr\boards\alientek\pandora_stm32l475\pandora_stm32l475.dts:88 */
				reg = < 0x0 >;                      /* in zephyr\boards\alientek\pandora_stm32l475\pandora_stm32l475.dts:89 */
				size = < 0x8000000 >;               /* in zephyr\boards\alientek\pandora_stm32l475\pandora_stm32l475.dts:90 */
				qspi-max-frequency = < 0x4c4b400 >; /* in zephyr\boards\alientek\pandora_stm32l475\pandora_stm32l475.dts:91 */
				cs-high-time = < 0x4 >;             /* in zephyr\boards\alientek\pandora_stm32l475\pandora_stm32l475.dts:92 */
				jedec-id = [ EF 40 18 ];            /* in zephyr\boards\alientek\pandora_stm32l475\pandora_stm32l475.dts:93 */
				spi-bus-width = < 0x4 >;            /* in zephyr\boards\alientek\pandora_stm32l475\pandora_stm32l475.dts:94 */
				writeoc = "PP_1_1_4";               /* in zephyr\boards\alientek\pandora_stm32l475\pandora_stm32l475.dts:95 */
				status = "okay";                    /* in zephyr\boards\alientek\pandora_stm32l475\pandora_stm32l475.dts:96 */
			};
		};

		/* node '/soc/spi@40013000' defined in zephyr\dts\arm\st\l4\stm32l4.dtsi:288 */
		spi1: spi@40013000 {
			compatible = "st,stm32-spi-fifo",
			             "st,stm32-spi";      /* in zephyr\dts\arm\st\l4\stm32l4.dtsi:289 */
			#address-cells = < 0x1 >;         /* in zephyr\dts\arm\st\l4\stm32l4.dtsi:290 */
			#size-cells = < 0x0 >;            /* in zephyr\dts\arm\st\l4\stm32l4.dtsi:291 */
			reg = < 0x40013000 0x400 >;       /* in zephyr\dts\arm\st\l4\stm32l4.dtsi:292 */
			interrupts = < 0x23 0x5 >;        /* in zephyr\dts\arm\st\l4\stm32l4.dtsi:293 */
			clocks = < &rcc 0x60 0x1000 >;    /* in zephyr\dts\arm\st\l4\stm32l4.dtsi:294 */
			status = "disabled";              /* in zephyr\dts\arm\st\l4\stm32l4.dtsi:295 */
		};

		/* node '/soc/timers@40012c00' defined in zephyr\dts\arm\st\l4\stm32l4.dtsi:298 */
		timers1: timers@40012c00 {
			compatible = "st,stm32-timers"; /* in zephyr\dts\arm\st\l4\stm32l4.dtsi:299 */
			reg = < 0x40012c00 0x400 >;     /* in zephyr\dts\arm\st\l4\stm32l4.dtsi:300 */
			clocks = < &rcc 0x60 0x800 >,
			         < &rcc 0x9 0xff >;     /* in zephyr\dts\arm\st\l4\stm32l4.dtsi:301 */
			resets = < &rctl 0x80b >;       /* in zephyr\dts\arm\st\l4\stm32l4.dtsi:303 */
			interrupts = < 0x18 0x0 >,
			             < 0x19 0x0 >,
			             < 0x1a 0x0 >,
			             < 0x1b 0x0 >;      /* in zephyr\dts\arm\st\l4\stm32l4.dtsi:304 */
			interrupt-names = "brk",
			                  "up",
			                  "trgcom",
			                  "cc";         /* in zephyr\dts\arm\st\l4\stm32l4.dtsi:305 */
			st,prescaler = < 0x0 >;         /* in zephyr\dts\arm\st\l4\stm32l4.dtsi:306 */
			status = "disabled";            /* in zephyr\dts\arm\st\l4\stm32l4.dtsi:307 */

			/* node '/soc/timers@40012c00/pwm' defined in zephyr\dts\arm\st\l4\stm32l4.dtsi:309 */
			pwm {
				compatible = "st,stm32-pwm"; /* in zephyr\dts\arm\st\l4\stm32l4.dtsi:310 */
				status = "disabled";         /* in zephyr\dts\arm\st\l4\stm32l4.dtsi:311 */
				#pwm-cells = < 0x3 >;        /* in zephyr\dts\arm\st\l4\stm32l4.dtsi:312 */
			};

			/* node '/soc/timers@40012c00/qdec' defined in zephyr\dts\arm\st\l4\stm32l4.dtsi:315 */
			qdec {
				compatible = "st,stm32-qdec";    /* in zephyr\dts\arm\st\l4\stm32l4.dtsi:316 */
				st,input-filter-level = < 0x0 >; /* in zephyr\dts\arm\st\l4\stm32l4.dtsi:317 */
				status = "disabled";             /* in zephyr\dts\arm\st\l4\stm32l4.dtsi:318 */
			};
		};

		/* node '/soc/timers@40000000' defined in zephyr\dts\arm\st\l4\stm32l4.dtsi:322 */
		timers2: timers@40000000 {
			compatible = "st,stm32-timers"; /* in zephyr\dts\arm\st\l4\stm32l4.dtsi:323 */
			reg = < 0x40000000 0x400 >;     /* in zephyr\dts\arm\st\l4\stm32l4.dtsi:324 */
			clocks = < &rcc 0x58 0x1 >,
			         < &rcc 0x8 0xff >;     /* in zephyr\dts\arm\st\l4\stm32l4.dtsi:325 */
			resets = < &rctl 0x700 >;       /* in zephyr\dts\arm\st\l4\stm32l4.dtsi:327 */
			interrupts = < 0x1c 0x0 >;      /* in zephyr\dts\arm\st\l4\stm32l4.dtsi:328 */
			interrupt-names = "global";     /* in zephyr\dts\arm\st\l4\stm32l4.dtsi:329 */
			st,prescaler = < 0x0 >;         /* in zephyr\dts\arm\st\l4\stm32l4.dtsi:330 */
			status = "disabled";            /* in zephyr\dts\arm\st\l4\stm32l4.dtsi:331 */

			/* node '/soc/timers@40000000/pwm' defined in zephyr\dts\arm\st\l4\stm32l4.dtsi:333 */
			pwm {
				compatible = "st,stm32-pwm"; /* in zephyr\dts\arm\st\l4\stm32l4.dtsi:334 */
				status = "disabled";         /* in zephyr\dts\arm\st\l4\stm32l4.dtsi:335 */
				#pwm-cells = < 0x3 >;        /* in zephyr\dts\arm\st\l4\stm32l4.dtsi:336 */
			};

			/* node '/soc/timers@40000000/counter' defined in zephyr\dts\arm\st\l4\stm32l4.dtsi:339 */
			counter {
				compatible = "st,stm32-counter"; /* in zephyr\dts\arm\st\l4\stm32l4.dtsi:340 */
				status = "disabled";             /* in zephyr\dts\arm\st\l4\stm32l4.dtsi:341 */
			};

			/* node '/soc/timers@40000000/qdec' defined in zephyr\dts\arm\st\l4\stm32l4.dtsi:344 */
			qdec {
				compatible = "st,stm32-qdec";    /* in zephyr\dts\arm\st\l4\stm32l4.dtsi:345 */
				st,input-filter-level = < 0x0 >; /* in zephyr\dts\arm\st\l4\stm32l4.dtsi:346 */
				status = "disabled";             /* in zephyr\dts\arm\st\l4\stm32l4.dtsi:347 */
			};
		};

		/* node '/soc/timers@40001000' defined in zephyr\dts\arm\st\l4\stm32l4.dtsi:351 */
		timers6: timers@40001000 {
			compatible = "st,stm32-timers"; /* in zephyr\dts\arm\st\l4\stm32l4.dtsi:352 */
			reg = < 0x40001000 0x400 >;     /* in zephyr\dts\arm\st\l4\stm32l4.dtsi:353 */
			clocks = < &rcc 0x58 0x10 >,
			         < &rcc 0x8 0xff >;     /* in zephyr\dts\arm\st\l4\stm32l4.dtsi:354 */
			resets = < &rctl 0x704 >;       /* in zephyr\dts\arm\st\l4\stm32l4.dtsi:356 */
			interrupts = < 0x36 0x0 >;      /* in zephyr\dts\arm\st\l4\stm32l4.dtsi:357 */
			interrupt-names = "global";     /* in zephyr\dts\arm\st\l4\stm32l4.dtsi:358 */
			st,prescaler = < 0x0 >;         /* in zephyr\dts\arm\st\l4\stm32l4.dtsi:359 */
			status = "disabled";            /* in zephyr\dts\arm\st\l4\stm32l4.dtsi:360 */

			/* node '/soc/timers@40001000/counter' defined in zephyr\dts\arm\st\l4\stm32l4.dtsi:362 */
			counter {
				compatible = "st,stm32-counter"; /* in zephyr\dts\arm\st\l4\stm32l4.dtsi:363 */
				status = "disabled";             /* in zephyr\dts\arm\st\l4\stm32l4.dtsi:364 */
			};
		};

		/* node '/soc/timers@40014000' defined in zephyr\dts\arm\st\l4\stm32l4.dtsi:368 */
		timers15: timers@40014000 {
			compatible = "st,stm32-timers"; /* in zephyr\dts\arm\st\l4\stm32l4.dtsi:369 */
			reg = < 0x40014000 0x400 >;     /* in zephyr\dts\arm\st\l4\stm32l4.dtsi:370 */
			clocks = < &rcc 0x60 0x10000 >,
			         < &rcc 0x9 0xff >;     /* in zephyr\dts\arm\st\l4\stm32l4.dtsi:371 */
			resets = < &rctl 0x810 >;       /* in zephyr\dts\arm\st\l4\stm32l4.dtsi:373 */
			interrupts = < 0x18 0x0 >;      /* in zephyr\dts\arm\st\l4\stm32l4.dtsi:374 */
			interrupt-names = "global";     /* in zephyr\dts\arm\st\l4\stm32l4.dtsi:375 */
			st,prescaler = < 0x0 >;         /* in zephyr\dts\arm\st\l4\stm32l4.dtsi:376 */
			status = "disabled";            /* in zephyr\dts\arm\st\l4\stm32l4.dtsi:377 */

			/* node '/soc/timers@40014000/pwm' defined in zephyr\dts\arm\st\l4\stm32l4.dtsi:379 */
			pwm {
				compatible = "st,stm32-pwm"; /* in zephyr\dts\arm\st\l4\stm32l4.dtsi:380 */
				status = "disabled";         /* in zephyr\dts\arm\st\l4\stm32l4.dtsi:381 */
				#pwm-cells = < 0x3 >;        /* in zephyr\dts\arm\st\l4\stm32l4.dtsi:382 */
			};

			/* node '/soc/timers@40014000/counter' defined in zephyr\dts\arm\st\l4\stm32l4.dtsi:385 */
			counter {
				compatible = "st,stm32-counter"; /* in zephyr\dts\arm\st\l4\stm32l4.dtsi:386 */
				status = "disabled";             /* in zephyr\dts\arm\st\l4\stm32l4.dtsi:387 */
			};
		};

		/* node '/soc/timers@40014400' defined in zephyr\dts\arm\st\l4\stm32l4.dtsi:391 */
		timers16: timers@40014400 {
			compatible = "st,stm32-timers"; /* in zephyr\dts\arm\st\l4\stm32l4.dtsi:392 */
			reg = < 0x40014400 0x400 >;     /* in zephyr\dts\arm\st\l4\stm32l4.dtsi:393 */
			clocks = < &rcc 0x60 0x20000 >,
			         < &rcc 0x9 0xff >;     /* in zephyr\dts\arm\st\l4\stm32l4.dtsi:394 */
			resets = < &rctl 0x811 >;       /* in zephyr\dts\arm\st\l4\stm32l4.dtsi:396 */
			interrupts = < 0x19 0x0 >;      /* in zephyr\dts\arm\st\l4\stm32l4.dtsi:397 */
			interrupt-names = "global";     /* in zephyr\dts\arm\st\l4\stm32l4.dtsi:398 */
			st,prescaler = < 0x0 >;         /* in zephyr\dts\arm\st\l4\stm32l4.dtsi:399 */
			status = "disabled";            /* in zephyr\dts\arm\st\l4\stm32l4.dtsi:400 */

			/* node '/soc/timers@40014400/pwm' defined in zephyr\dts\arm\st\l4\stm32l4.dtsi:402 */
			pwm {
				compatible = "st,stm32-pwm"; /* in zephyr\dts\arm\st\l4\stm32l4.dtsi:403 */
				status = "disabled";         /* in zephyr\dts\arm\st\l4\stm32l4.dtsi:404 */
				#pwm-cells = < 0x3 >;        /* in zephyr\dts\arm\st\l4\stm32l4.dtsi:405 */
			};

			/* node '/soc/timers@40014400/counter' defined in zephyr\dts\arm\st\l4\stm32l4.dtsi:408 */
			counter {
				compatible = "st,stm32-counter"; /* in zephyr\dts\arm\st\l4\stm32l4.dtsi:409 */
				status = "disabled";             /* in zephyr\dts\arm\st\l4\stm32l4.dtsi:410 */
			};
		};

		/* node '/soc/rtc@40002800' defined in zephyr\dts\arm\st\l4\stm32l4.dtsi:414 */
		rtc: rtc@40002800 {
			compatible = "st,stm32-rtc";       /* in zephyr\dts\arm\st\l4\stm32l4.dtsi:415 */
			reg = < 0x40002800 0x400 >;        /* in zephyr\dts\arm\st\l4\stm32l4.dtsi:416 */
			interrupts = < 0x29 0x0 >;         /* in zephyr\dts\arm\st\l4\stm32l4.dtsi:417 */
			prescaler = < 0x8000 >;            /* in zephyr\dts\arm\st\l4\stm32l4.dtsi:419 */
			alarms-count = < 0x2 >;            /* in zephyr\dts\arm\st\l4\stm32l4.dtsi:420 */
			alrm-exti-line = < 0x12 >;         /* in zephyr\dts\arm\st\l4\stm32l4.dtsi:421 */
			clocks = < &rcc 0x58 0x10000000 >,
			         < &rcc 0x3 0x10c80090 >;  /* in zephyr\boards\alientek\pandora_stm32l475\pandora_stm32l475.dts:134 */
			status = "okay";                   /* in zephyr\boards\alientek\pandora_stm32l475\pandora_stm32l475.dts:136 */

			/* node '/soc/rtc@40002800/backup_regs' defined in zephyr\dts\arm\st\l4\stm32l471.dtsi:318 */
			bbram: backup_regs {
				compatible = "st,stm32-bbram"; /* in zephyr\dts\arm\st\l4\stm32l471.dtsi:319 */
				st,backup-regs = < 0x20 >;     /* in zephyr\dts\arm\st\l4\stm32l471.dtsi:320 */
				status = "okay";               /* in zephyr\boards\alientek\pandora_stm32l475\pandora_stm32l475.dts:139 */
			};
		};

		/* node '/soc/adc@50040000' defined in zephyr\dts\arm\st\l4\stm32l4.dtsi:425 */
		adc1: adc@50040000 {
			compatible = "st,stm32-adc";                                /* in zephyr\dts\arm\st\l4\stm32l4.dtsi:426 */
			reg = < 0x50040000 0x100 >;                                 /* in zephyr\dts\arm\st\l4\stm32l4.dtsi:427 */
			clocks = < &rcc 0x4c 0x2000 >;                              /* in zephyr\dts\arm\st\l4\stm32l4.dtsi:428 */
			interrupts = < 0x12 0x0 >;                                  /* in zephyr\dts\arm\st\l4\stm32l4.dtsi:429 */
			#io-channel-cells = < 0x1 >;                                /* in zephyr\dts\arm\st\l4\stm32l4.dtsi:430 */
			resolutions = < 0x60630c 0x51630c 0x42630c 0x33630c >;      /* in zephyr\dts\arm\st\l4\stm32l4.dtsi:431 */
			sampling-times = < 0x3 0x7 0xd 0x19 0x30 0x5d 0xf8 0x281 >; /* in zephyr\dts\arm\st\l4\stm32l4.dtsi:435 */
			st,adc-sequencer = "programmable";                          /* in zephyr\dts\arm\st\l4\stm32l4.dtsi:436 */
			st,adc-oversampler = "minimal";                             /* in zephyr\dts\arm\st\l4\stm32l4.dtsi:437 */
			st,adc-internal-regulator = "startup-sw-delay";             /* in zephyr\dts\arm\st\l4\stm32l4.dtsi:438 */
			st,adc-has-deep-powerdown;                                  /* in zephyr\dts\arm\st\l4\stm32l4.dtsi:439 */
			st,adc-has-differential-support;                            /* in zephyr\dts\arm\st\l4\stm32l4.dtsi:440 */
			status = "disabled";                                        /* in zephyr\dts\arm\st\l4\stm32l4.dtsi:441 */
			phandle = < 0x15 >;                                         /* in zephyr\dts\arm\st\l4\stm32l4.dtsi:558 */
		};

		/* node '/soc/adc@50040100' defined in zephyr\dts\arm\st\l4\stm32l4.dtsi:444 */
		adc2: adc@50040100 {
			compatible = "st,stm32-adc";                                /* in zephyr\dts\arm\st\l4\stm32l4.dtsi:445 */
			reg = < 0x50040100 0x100 >;                                 /* in zephyr\dts\arm\st\l4\stm32l4.dtsi:446 */
			clocks = < &rcc 0x4c 0x2000 >;                              /* in zephyr\dts\arm\st\l4\stm32l4.dtsi:447 */
			interrupts = < 0x12 0x0 >;                                  /* in zephyr\dts\arm\st\l4\stm32l4.dtsi:448 */
			#io-channel-cells = < 0x1 >;                                /* in zephyr\dts\arm\st\l4\stm32l4.dtsi:449 */
			resolutions = < 0x60630c 0x51630c 0x42630c 0x33630c >;      /* in zephyr\dts\arm\st\l4\stm32l4.dtsi:450 */
			sampling-times = < 0x3 0x7 0xd 0x19 0x30 0x5d 0xf8 0x281 >; /* in zephyr\dts\arm\st\l4\stm32l4.dtsi:454 */
			st,adc-sequencer = "programmable";                          /* in zephyr\dts\arm\st\l4\stm32l4.dtsi:455 */
			st,adc-oversampler = "minimal";                             /* in zephyr\dts\arm\st\l4\stm32l4.dtsi:456 */
			st,adc-internal-regulator = "startup-sw-delay";             /* in zephyr\dts\arm\st\l4\stm32l4.dtsi:457 */
			st,adc-has-deep-powerdown;                                  /* in zephyr\dts\arm\st\l4\stm32l4.dtsi:458 */
			st,adc-has-differential-support;                            /* in zephyr\dts\arm\st\l4\stm32l4.dtsi:459 */
			status = "disabled";                                        /* in zephyr\dts\arm\st\l4\stm32l4.dtsi:460 */
		};

		/* node '/soc/dma@40020000' defined in zephyr\dts\arm\st\l4\stm32l4.dtsi:463 */
		dma1: dma@40020000 {
			compatible = "st,stm32-dma-v2";                                             /* in zephyr\dts\arm\st\l4\stm32l4.dtsi:464 */
			#dma-cells = < 0x3 >;                                                       /* in zephyr\dts\arm\st\l4\stm32l4.dtsi:465 */
			reg = < 0x40020000 0x400 >;                                                 /* in zephyr\dts\arm\st\l4\stm32l4.dtsi:466 */
			interrupts = < 0xb 0x0 0xc 0x0 0xd 0x0 0xe 0x0 0xf 0x0 0x10 0x0 0x11 0x0 >; /* in zephyr\dts\arm\st\l4\stm32l4.dtsi:467 */
			clocks = < &rcc 0x48 0x1 >;                                                 /* in zephyr\dts\arm\st\l4\stm32l4.dtsi:468 */
			dma-requests = < 0x7 >;                                                     /* in zephyr\dts\arm\st\l4\stm32l4.dtsi:469 */
			status = "disabled";                                                        /* in zephyr\dts\arm\st\l4\stm32l4.dtsi:470 */
		};

		/* node '/soc/dma@40020400' defined in zephyr\dts\arm\st\l4\stm32l4.dtsi:473 */
		dma2: dma@40020400 {
			compatible = "st,stm32-dma-v2";                                                  /* in zephyr\dts\arm\st\l4\stm32l4.dtsi:474 */
			#dma-cells = < 0x3 >;                                                            /* in zephyr\dts\arm\st\l4\stm32l4.dtsi:475 */
			reg = < 0x40020400 0x400 >;                                                      /* in zephyr\dts\arm\st\l4\stm32l4.dtsi:476 */
			interrupts = < 0x38 0x0 0x39 0x0 0x3a 0x0 0x3b 0x0 0x3c 0x0 0x44 0x0 0x45 0x0 >; /* in zephyr\dts\arm\st\l4\stm32l4.dtsi:477 */
			clocks = < &rcc 0x48 0x2 >;                                                      /* in zephyr\dts\arm\st\l4\stm32l4.dtsi:478 */
			dma-requests = < 0x7 >;                                                          /* in zephyr\dts\arm\st\l4\stm32l4.dtsi:479 */
			status = "disabled";                                                             /* in zephyr\dts\arm\st\l4\stm32l4.dtsi:480 */
			phandle = < 0x18 >;                                                              /* in zephyr\dts\arm\st\l4\stm32l4.dtsi:600 */
		};

		/* node '/soc/timers@40007c00' defined in zephyr\dts\arm\st\l4\stm32l4.dtsi:483 */
		lptim1: timers@40007c00 {
			compatible = "st,stm32-lptim";     /* in zephyr\dts\arm\st\l4\stm32l4.dtsi:484 */
			clocks = < &rcc 0x58 0x80000000 >; /* in zephyr\dts\arm\st\l4\stm32l4.dtsi:485 */
			#address-cells = < 0x1 >;          /* in zephyr\dts\arm\st\l4\stm32l4.dtsi:486 */
			#size-cells = < 0x0 >;             /* in zephyr\dts\arm\st\l4\stm32l4.dtsi:487 */
			reg = < 0x40007c00 0x400 >;        /* in zephyr\dts\arm\st\l4\stm32l4.dtsi:488 */
			interrupts = < 0x41 0x1 >;         /* in zephyr\dts\arm\st\l4\stm32l4.dtsi:489 */
			interrupt-names = "wakeup";        /* in zephyr\dts\arm\st\l4\stm32l4.dtsi:490 */
			status = "disabled";               /* in zephyr\dts\arm\st\l4\stm32l4.dtsi:491 */
		};

		/* node '/soc/timers@40009400' defined in zephyr\dts\arm\st\l4\stm32l4.dtsi:494 */
		lptim2: timers@40009400 {
			compatible = "st,stm32-lptim"; /* in zephyr\dts\arm\st\l4\stm32l4.dtsi:495 */
			#address-cells = < 0x1 >;      /* in zephyr\dts\arm\st\l4\stm32l4.dtsi:496 */
			#size-cells = < 0x0 >;         /* in zephyr\dts\arm\st\l4\stm32l4.dtsi:497 */
			reg = < 0x40009400 0x400 >;    /* in zephyr\dts\arm\st\l4\stm32l4.dtsi:498 */
			clocks = < &rcc 0x5c 0x20 >;   /* in zephyr\dts\arm\st\l4\stm32l4.dtsi:499 */
			interrupts = < 0x42 0x1 >;     /* in zephyr\dts\arm\st\l4\stm32l4.dtsi:500 */
			interrupt-names = "wakeup";    /* in zephyr\dts\arm\st\l4\stm32l4.dtsi:501 */
			status = "disabled";           /* in zephyr\dts\arm\st\l4\stm32l4.dtsi:502 */
		};

		/* node '/soc/rng@50060800' defined in zephyr\dts\arm\st\l4\stm32l4.dtsi:505 */
		rng: rng@50060800 {
			compatible = "st,stm32-rng";      /* in zephyr\dts\arm\st\l4\stm32l4.dtsi:506 */
			reg = < 0x50060800 0x400 >;       /* in zephyr\dts\arm\st\l4\stm32l4.dtsi:507 */
			interrupts = < 0x50 0x0 >;        /* in zephyr\dts\arm\st\l4\stm32l4.dtsi:508 */
			clocks = < &rcc 0x4c 0x40000 >,
			         < &rcc 0x6 0x18da0088 >; /* in zephyr\dts\arm\st\l4\stm32l4.dtsi:509 */
			status = "disabled";              /* in zephyr\dts\arm\st\l4\stm32l4.dtsi:514 */
		};

		/* node '/soc/power@40007000' defined in zephyr\dts\arm\st\l4\stm32l4.dtsi:517 */
		pwr: power@40007000 {
			compatible = "st,stm32-pwr"; /* in zephyr\dts\arm\st\l4\stm32l4.dtsi:518 */
			reg = < 0x40007000 0x400 >;  /* in zephyr\dts\arm\st\l4\stm32l4.dtsi:519 */
			status = "disabled";         /* in zephyr\dts\arm\st\l4\stm32l4.dtsi:520 */
			wkup-pins-nb = < 0x5 >;      /* in zephyr\dts\arm\st\l4\stm32l4.dtsi:522 */
			wkup-pins-pol;               /* in zephyr\dts\arm\st\l4\stm32l4.dtsi:523 */
			wkup-pins-pupd;              /* in zephyr\dts\arm\st\l4\stm32l4.dtsi:524 */
			#address-cells = < 0x1 >;    /* in zephyr\dts\arm\st\l4\stm32l4.dtsi:526 */
			#size-cells = < 0x0 >;       /* in zephyr\dts\arm\st\l4\stm32l4.dtsi:527 */

			/* node '/soc/power@40007000/wkup-pin@1' defined in zephyr\dts\arm\st\l4\stm32l4.dtsi:529 */
			wkup-pin@1 {
				reg = < 0x1 >; /* in zephyr\dts\arm\st\l4\stm32l4.dtsi:530 */
			};

			/* node '/soc/power@40007000/wkup-pin@2' defined in zephyr\dts\arm\st\l4\stm32l4.dtsi:533 */
			wkup-pin@2 {
				reg = < 0x2 >; /* in zephyr\dts\arm\st\l4\stm32l4.dtsi:534 */
			};

			/* node '/soc/power@40007000/wkup-pin@3' defined in zephyr\dts\arm\st\l4\stm32l4.dtsi:537 */
			wkup-pin@3 {
				reg = < 0x3 >; /* in zephyr\dts\arm\st\l4\stm32l4.dtsi:538 */
			};

			/* node '/soc/power@40007000/wkup-pin@4' defined in zephyr\dts\arm\st\l4\stm32l4.dtsi:541 */
			wkup-pin@4 {
				reg = < 0x4 >; /* in zephyr\dts\arm\st\l4\stm32l4.dtsi:542 */
			};

			/* node '/soc/power@40007000/wkup-pin@5' defined in zephyr\dts\arm\st\l4\stm32l4.dtsi:545 */
			wkup-pin@5 {
				reg = < 0x5 >; /* in zephyr\dts\arm\st\l4\stm32l4.dtsi:546 */
			};
		};

		/* node '/soc/serial@40004800' defined in zephyr\dts\arm\st\l4\stm32l471.dtsi:61 */
		usart3: serial@40004800 {
			compatible = "st,stm32-usart",
			             "st,stm32-uart";   /* in zephyr\dts\arm\st\l4\stm32l471.dtsi:62 */
			reg = < 0x40004800 0x400 >;     /* in zephyr\dts\arm\st\l4\stm32l471.dtsi:63 */
			clocks = < &rcc 0x58 0x40000 >; /* in zephyr\dts\arm\st\l4\stm32l471.dtsi:64 */
			resets = < &rctl 0x712 >;       /* in zephyr\dts\arm\st\l4\stm32l471.dtsi:65 */
			interrupts = < 0x27 0x0 >;      /* in zephyr\dts\arm\st\l4\stm32l471.dtsi:66 */
			status = "disabled";            /* in zephyr\dts\arm\st\l4\stm32l471.dtsi:67 */
		};

		/* node '/soc/serial@40004c00' defined in zephyr\dts\arm\st\l4\stm32l471.dtsi:70 */
		uart4: serial@40004c00 {
			compatible = "st,stm32-uart";   /* in zephyr\dts\arm\st\l4\stm32l471.dtsi:71 */
			reg = < 0x40004c00 0x400 >;     /* in zephyr\dts\arm\st\l4\stm32l471.dtsi:72 */
			clocks = < &rcc 0x58 0x80000 >; /* in zephyr\dts\arm\st\l4\stm32l471.dtsi:73 */
			resets = < &rctl 0x713 >;       /* in zephyr\dts\arm\st\l4\stm32l471.dtsi:74 */
			interrupts = < 0x34 0x0 >;      /* in zephyr\dts\arm\st\l4\stm32l471.dtsi:75 */
			status = "disabled";            /* in zephyr\dts\arm\st\l4\stm32l471.dtsi:76 */
		};

		/* node '/soc/serial@40005000' defined in zephyr\dts\arm\st\l4\stm32l471.dtsi:79 */
		uart5: serial@40005000 {
			compatible = "st,stm32-uart";    /* in zephyr\dts\arm\st\l4\stm32l471.dtsi:80 */
			reg = < 0x40005000 0x400 >;      /* in zephyr\dts\arm\st\l4\stm32l471.dtsi:81 */
			clocks = < &rcc 0x58 0x100000 >; /* in zephyr\dts\arm\st\l4\stm32l471.dtsi:82 */
			resets = < &rctl 0x714 >;        /* in zephyr\dts\arm\st\l4\stm32l471.dtsi:83 */
			interrupts = < 0x35 0x0 >;       /* in zephyr\dts\arm\st\l4\stm32l471.dtsi:84 */
			status = "disabled";             /* in zephyr\dts\arm\st\l4\stm32l471.dtsi:85 */
		};

		/* node '/soc/i2c@40005800' defined in zephyr\dts\arm\st\l4\stm32l471.dtsi:88 */
		i2c2: i2c@40005800 {
			compatible = "st,stm32-i2c-v2";  /* in zephyr\dts\arm\st\l4\stm32l471.dtsi:89 */
			clock-frequency = < 0x186a0 >;   /* in zephyr\dts\arm\st\l4\stm32l471.dtsi:90 */
			#address-cells = < 0x1 >;        /* in zephyr\dts\arm\st\l4\stm32l471.dtsi:91 */
			#size-cells = < 0x0 >;           /* in zephyr\dts\arm\st\l4\stm32l471.dtsi:92 */
			reg = < 0x40005800 0x400 >;      /* in zephyr\dts\arm\st\l4\stm32l471.dtsi:93 */
			clocks = < &rcc 0x58 0x400000 >; /* in zephyr\dts\arm\st\l4\stm32l471.dtsi:94 */
			interrupts = < 0x21 0x0 >,
			             < 0x22 0x0 >;       /* in zephyr\dts\arm\st\l4\stm32l471.dtsi:95 */
			interrupt-names = "event",
			                  "error";       /* in zephyr\dts\arm\st\l4\stm32l471.dtsi:96 */
			status = "disabled";             /* in zephyr\dts\arm\st\l4\stm32l471.dtsi:97 */
			phandle = < 0x19 >;              /* in zephyr\dts\arm\st\l4\stm32l471.dtsi:334 */
		};

		/* node '/soc/spi@40003800' defined in zephyr\dts\arm\st\l4\stm32l471.dtsi:100 */
		spi2: spi@40003800 {
			compatible = "st,stm32-spi-fifo",
			             "st,stm32-spi";      /* in zephyr\dts\arm\st\l4\stm32l471.dtsi:101 */
			#address-cells = < 0x1 >;         /* in zephyr\dts\arm\st\l4\stm32l471.dtsi:102 */
			#size-cells = < 0x0 >;            /* in zephyr\dts\arm\st\l4\stm32l471.dtsi:103 */
			reg = < 0x40003800 0x400 >;       /* in zephyr\dts\arm\st\l4\stm32l471.dtsi:104 */
			clocks = < &rcc 0x58 0x4000 >;    /* in zephyr\dts\arm\st\l4\stm32l471.dtsi:105 */
			interrupts = < 0x24 0x5 >;        /* in zephyr\dts\arm\st\l4\stm32l471.dtsi:106 */
			status = "disabled";              /* in zephyr\dts\arm\st\l4\stm32l471.dtsi:107 */
		};

		/* node '/soc/spi@40003c00' defined in zephyr\dts\arm\st\l4\stm32l471.dtsi:110 */
		spi3: spi@40003c00 {
			compatible = "st,stm32-spi-fifo",
			             "st,stm32-spi";      /* in zephyr\dts\arm\st\l4\stm32l471.dtsi:111 */
			#address-cells = < 0x1 >;         /* in zephyr\dts\arm\st\l4\stm32l471.dtsi:112 */
			#size-cells = < 0x0 >;            /* in zephyr\dts\arm\st\l4\stm32l471.dtsi:113 */
			reg = < 0x40003c00 0x400 >;       /* in zephyr\dts\arm\st\l4\stm32l471.dtsi:114 */
			clocks = < &rcc 0x58 0x8000 >;    /* in zephyr\dts\arm\st\l4\stm32l471.dtsi:115 */
			interrupts = < 0x33 0x5 >;        /* in zephyr\dts\arm\st\l4\stm32l471.dtsi:116 */
			status = "disabled";              /* in zephyr\dts\arm\st\l4\stm32l471.dtsi:117 */
		};

		/* node '/soc/timers@40000400' defined in zephyr\dts\arm\st\l4\stm32l471.dtsi:120 */
		timers3: timers@40000400 {
			compatible = "st,stm32-timers"; /* in zephyr\dts\arm\st\l4\stm32l471.dtsi:121 */
			reg = < 0x40000400 0x400 >;     /* in zephyr\dts\arm\st\l4\stm32l471.dtsi:122 */
			clocks = < &rcc 0x58 0x2 >,
			         < &rcc 0x8 0xff >;     /* in zephyr\dts\arm\st\l4\stm32l471.dtsi:123 */
			resets = < &rctl 0x701 >;       /* in zephyr\dts\arm\st\l4\stm32l471.dtsi:125 */
			interrupts = < 0x1d 0x0 >;      /* in zephyr\dts\arm\st\l4\stm32l471.dtsi:126 */
			interrupt-names = "global";     /* in zephyr\dts\arm\st\l4\stm32l471.dtsi:127 */
			st,prescaler = < 0x0 >;         /* in zephyr\dts\arm\st\l4\stm32l471.dtsi:128 */
			status = "disabled";            /* in zephyr\dts\arm\st\l4\stm32l471.dtsi:129 */

			/* node '/soc/timers@40000400/pwm' defined in zephyr\dts\arm\st\l4\stm32l471.dtsi:131 */
			pwm {
				compatible = "st,stm32-pwm"; /* in zephyr\dts\arm\st\l4\stm32l471.dtsi:132 */
				status = "disabled";         /* in zephyr\dts\arm\st\l4\stm32l471.dtsi:133 */
				#pwm-cells = < 0x3 >;        /* in zephyr\dts\arm\st\l4\stm32l471.dtsi:134 */
			};

			/* node '/soc/timers@40000400/counter' defined in zephyr\dts\arm\st\l4\stm32l471.dtsi:137 */
			counter {
				compatible = "st,stm32-counter"; /* in zephyr\dts\arm\st\l4\stm32l471.dtsi:138 */
				status = "disabled";             /* in zephyr\dts\arm\st\l4\stm32l471.dtsi:139 */
			};

			/* node '/soc/timers@40000400/qdec' defined in zephyr\dts\arm\st\l4\stm32l471.dtsi:142 */
			qdec {
				compatible = "st,stm32-qdec";    /* in zephyr\dts\arm\st\l4\stm32l471.dtsi:143 */
				st,input-filter-level = < 0x0 >; /* in zephyr\dts\arm\st\l4\stm32l471.dtsi:144 */
				status = "disabled";             /* in zephyr\dts\arm\st\l4\stm32l471.dtsi:145 */
			};
		};

		/* node '/soc/timers@40000800' defined in zephyr\dts\arm\st\l4\stm32l471.dtsi:149 */
		timers4: timers@40000800 {
			compatible = "st,stm32-timers"; /* in zephyr\dts\arm\st\l4\stm32l471.dtsi:150 */
			reg = < 0x40000800 0x400 >;     /* in zephyr\dts\arm\st\l4\stm32l471.dtsi:151 */
			clocks = < &rcc 0x58 0x4 >,
			         < &rcc 0x8 0xff >;     /* in zephyr\dts\arm\st\l4\stm32l471.dtsi:152 */
			resets = < &rctl 0x702 >;       /* in zephyr\dts\arm\st\l4\stm32l471.dtsi:154 */
			interrupts = < 0x1e 0x0 >;      /* in zephyr\dts\arm\st\l4\stm32l471.dtsi:155 */
			interrupt-names = "global";     /* in zephyr\dts\arm\st\l4\stm32l471.dtsi:156 */
			status = "okay";                /* in application\pandora_stm32l475.overlay:58 */
			st,prescaler = < 0x640 >;       /* in application\pandora_stm32l475.overlay:60 */

			/* node '/soc/timers@40000800/pwm' defined in zephyr\dts\arm\st\l4\stm32l471.dtsi:160 */
			pwm4: pwm {
				compatible = "st,stm32-pwm";   /* in zephyr\dts\arm\st\l4\stm32l471.dtsi:161 */
				#pwm-cells = < 0x3 >;          /* in zephyr\dts\arm\st\l4\stm32l471.dtsi:163 */
				status = "okay";               /* in application\pandora_stm32l475.overlay:63 */
				pinctrl-0 = < &tim4_ch3_pb8 >; /* in application\pandora_stm32l475.overlay:64 */
				pinctrl-names = "default";     /* in application\pandora_stm32l475.overlay:65 */
				phandle = < 0x1d >;            /* in application\pandora_stm32l475.overlay:9 */
			};

			/* node '/soc/timers@40000800/counter' defined in zephyr\dts\arm\st\l4\stm32l471.dtsi:166 */
			counter {
				compatible = "st,stm32-counter"; /* in zephyr\dts\arm\st\l4\stm32l471.dtsi:167 */
				status = "disabled";             /* in zephyr\dts\arm\st\l4\stm32l471.dtsi:168 */
			};

			/* node '/soc/timers@40000800/qdec' defined in zephyr\dts\arm\st\l4\stm32l471.dtsi:171 */
			qdec {
				compatible = "st,stm32-qdec";    /* in zephyr\dts\arm\st\l4\stm32l471.dtsi:172 */
				st,input-filter-level = < 0x0 >; /* in zephyr\dts\arm\st\l4\stm32l471.dtsi:173 */
				status = "disabled";             /* in zephyr\dts\arm\st\l4\stm32l471.dtsi:174 */
			};
		};

		/* node '/soc/timers@40000c00' defined in zephyr\dts\arm\st\l4\stm32l471.dtsi:178 */
		timers5: timers@40000c00 {
			compatible = "st,stm32-timers"; /* in zephyr\dts\arm\st\l4\stm32l471.dtsi:179 */
			reg = < 0x40000c00 0x400 >;     /* in zephyr\dts\arm\st\l4\stm32l471.dtsi:180 */
			clocks = < &rcc 0x58 0x8 >,
			         < &rcc 0x8 0xff >;     /* in zephyr\dts\arm\st\l4\stm32l471.dtsi:181 */
			resets = < &rctl 0x703 >;       /* in zephyr\dts\arm\st\l4\stm32l471.dtsi:183 */
			interrupts = < 0x32 0x0 >;      /* in zephyr\dts\arm\st\l4\stm32l471.dtsi:184 */
			interrupt-names = "global";     /* in zephyr\dts\arm\st\l4\stm32l471.dtsi:185 */
			st,prescaler = < 0x0 >;         /* in zephyr\dts\arm\st\l4\stm32l471.dtsi:186 */
			status = "disabled";            /* in zephyr\dts\arm\st\l4\stm32l471.dtsi:187 */

			/* node '/soc/timers@40000c00/pwm' defined in zephyr\dts\arm\st\l4\stm32l471.dtsi:189 */
			pwm {
				compatible = "st,stm32-pwm"; /* in zephyr\dts\arm\st\l4\stm32l471.dtsi:190 */
				status = "disabled";         /* in zephyr\dts\arm\st\l4\stm32l471.dtsi:191 */
				#pwm-cells = < 0x3 >;        /* in zephyr\dts\arm\st\l4\stm32l471.dtsi:192 */
			};

			/* node '/soc/timers@40000c00/counter' defined in zephyr\dts\arm\st\l4\stm32l471.dtsi:195 */
			counter {
				compatible = "st,stm32-counter"; /* in zephyr\dts\arm\st\l4\stm32l471.dtsi:196 */
				status = "disabled";             /* in zephyr\dts\arm\st\l4\stm32l471.dtsi:197 */
			};

			/* node '/soc/timers@40000c00/qdec' defined in zephyr\dts\arm\st\l4\stm32l471.dtsi:200 */
			qdec {
				compatible = "st,stm32-qdec";    /* in zephyr\dts\arm\st\l4\stm32l471.dtsi:201 */
				st,input-filter-level = < 0x0 >; /* in zephyr\dts\arm\st\l4\stm32l471.dtsi:202 */
				status = "disabled";             /* in zephyr\dts\arm\st\l4\stm32l471.dtsi:203 */
			};
		};

		/* node '/soc/timers@40001400' defined in zephyr\dts\arm\st\l4\stm32l471.dtsi:207 */
		timers7: timers@40001400 {
			compatible = "st,stm32-timers"; /* in zephyr\dts\arm\st\l4\stm32l471.dtsi:208 */
			reg = < 0x40001400 0x400 >;     /* in zephyr\dts\arm\st\l4\stm32l471.dtsi:209 */
			clocks = < &rcc 0x58 0x20 >,
			         < &rcc 0x8 0xff >;     /* in zephyr\dts\arm\st\l4\stm32l471.dtsi:210 */
			resets = < &rctl 0x705 >;       /* in zephyr\dts\arm\st\l4\stm32l471.dtsi:212 */
			interrupts = < 0x37 0x0 >;      /* in zephyr\dts\arm\st\l4\stm32l471.dtsi:213 */
			interrupt-names = "global";     /* in zephyr\dts\arm\st\l4\stm32l471.dtsi:214 */
			st,prescaler = < 0x0 >;         /* in zephyr\dts\arm\st\l4\stm32l471.dtsi:215 */
			status = "disabled";            /* in zephyr\dts\arm\st\l4\stm32l471.dtsi:216 */

			/* node '/soc/timers@40001400/counter' defined in zephyr\dts\arm\st\l4\stm32l471.dtsi:218 */
			counter {
				compatible = "st,stm32-counter"; /* in zephyr\dts\arm\st\l4\stm32l471.dtsi:219 */
				status = "disabled";             /* in zephyr\dts\arm\st\l4\stm32l471.dtsi:220 */
			};
		};

		/* node '/soc/timers@40013400' defined in zephyr\dts\arm\st\l4\stm32l471.dtsi:224 */
		timers8: timers@40013400 {
			compatible = "st,stm32-timers"; /* in zephyr\dts\arm\st\l4\stm32l471.dtsi:225 */
			reg = < 0x40013400 0x400 >;     /* in zephyr\dts\arm\st\l4\stm32l471.dtsi:226 */
			clocks = < &rcc 0x60 0x2000 >,
			         < &rcc 0x9 0xff >;     /* in zephyr\dts\arm\st\l4\stm32l471.dtsi:227 */
			resets = < &rctl 0x80d >;       /* in zephyr\dts\arm\st\l4\stm32l471.dtsi:229 */
			interrupts = < 0x2b 0x0 >,
			             < 0x2c 0x0 >,
			             < 0x2d 0x0 >,
			             < 0x2e 0x0 >;      /* in zephyr\dts\arm\st\l4\stm32l471.dtsi:230 */
			interrupt-names = "brk",
			                  "up",
			                  "trgcom",
			                  "cc";         /* in zephyr\dts\arm\st\l4\stm32l471.dtsi:231 */
			st,prescaler = < 0x0 >;         /* in zephyr\dts\arm\st\l4\stm32l471.dtsi:232 */
			status = "disabled";            /* in zephyr\dts\arm\st\l4\stm32l471.dtsi:233 */

			/* node '/soc/timers@40013400/pwm' defined in zephyr\dts\arm\st\l4\stm32l471.dtsi:235 */
			pwm {
				compatible = "st,stm32-pwm"; /* in zephyr\dts\arm\st\l4\stm32l471.dtsi:236 */
				status = "disabled";         /* in zephyr\dts\arm\st\l4\stm32l471.dtsi:237 */
				#pwm-cells = < 0x3 >;        /* in zephyr\dts\arm\st\l4\stm32l471.dtsi:238 */
			};

			/* node '/soc/timers@40013400/qdec' defined in zephyr\dts\arm\st\l4\stm32l471.dtsi:241 */
			qdec {
				compatible = "st,stm32-qdec";    /* in zephyr\dts\arm\st\l4\stm32l471.dtsi:242 */
				st,input-filter-level = < 0x0 >; /* in zephyr\dts\arm\st\l4\stm32l471.dtsi:243 */
				status = "disabled";             /* in zephyr\dts\arm\st\l4\stm32l471.dtsi:244 */
			};
		};

		/* node '/soc/timers@40014800' defined in zephyr\dts\arm\st\l4\stm32l471.dtsi:248 */
		timers17: timers@40014800 {
			compatible = "st,stm32-timers"; /* in zephyr\dts\arm\st\l4\stm32l471.dtsi:249 */
			reg = < 0x40014800 0x400 >;     /* in zephyr\dts\arm\st\l4\stm32l471.dtsi:250 */
			clocks = < &rcc 0x60 0x40000 >,
			         < &rcc 0x9 0xff >;     /* in zephyr\dts\arm\st\l4\stm32l471.dtsi:251 */
			resets = < &rctl 0x812 >;       /* in zephyr\dts\arm\st\l4\stm32l471.dtsi:253 */
			interrupts = < 0x1a 0x0 >;      /* in zephyr\dts\arm\st\l4\stm32l471.dtsi:254 */
			interrupt-names = "global";     /* in zephyr\dts\arm\st\l4\stm32l471.dtsi:255 */
			st,prescaler = < 0x0 >;         /* in zephyr\dts\arm\st\l4\stm32l471.dtsi:256 */
			status = "disabled";            /* in zephyr\dts\arm\st\l4\stm32l471.dtsi:257 */

			/* node '/soc/timers@40014800/pwm' defined in zephyr\dts\arm\st\l4\stm32l471.dtsi:259 */
			pwm {
				compatible = "st,stm32-pwm"; /* in zephyr\dts\arm\st\l4\stm32l471.dtsi:260 */
				status = "disabled";         /* in zephyr\dts\arm\st\l4\stm32l471.dtsi:261 */
				#pwm-cells = < 0x3 >;        /* in zephyr\dts\arm\st\l4\stm32l471.dtsi:262 */
			};

			/* node '/soc/timers@40014800/counter' defined in zephyr\dts\arm\st\l4\stm32l471.dtsi:265 */
			counter {
				compatible = "st,stm32-counter"; /* in zephyr\dts\arm\st\l4\stm32l471.dtsi:266 */
				status = "disabled";             /* in zephyr\dts\arm\st\l4\stm32l471.dtsi:267 */
			};
		};

		/* node '/soc/can@40006400' defined in zephyr\dts\arm\st\l4\stm32l471.dtsi:271 */
		can1: can@40006400 {
			compatible = "st,stm32-bxcan";    /* in zephyr\dts\arm\st\l4\stm32l471.dtsi:272 */
			reg = < 0x40006400 0x400 >;       /* in zephyr\dts\arm\st\l4\stm32l471.dtsi:273 */
			interrupts = < 0x13 0x0 >,
			             < 0x14 0x0 >,
			             < 0x15 0x0 >,
			             < 0x16 0x0 >;        /* in zephyr\dts\arm\st\l4\stm32l471.dtsi:274 */
			interrupt-names = "TX",
			                  "RX0",
			                  "RX1",
			                  "SCE";          /* in zephyr\dts\arm\st\l4\stm32l471.dtsi:275 */
			clocks = < &rcc 0x58 0x2000000 >; /* in zephyr\dts\arm\st\l4\stm32l471.dtsi:276 */
			status = "disabled";              /* in zephyr\dts\arm\st\l4\stm32l471.dtsi:277 */
		};

		/* node '/soc/sdmmc@40012800' defined in zephyr\dts\arm\st\l4\stm32l471.dtsi:280 */
		sdmmc1: sdmmc@40012800 {
			compatible = "st,stm32-sdmmc";    /* in zephyr\dts\arm\st\l4\stm32l471.dtsi:281 */
			reg = < 0x40012800 0x400 >;       /* in zephyr\dts\arm\st\l4\stm32l471.dtsi:282 */
			clocks = < &rcc 0x60 0x400 >,
			         < &rcc 0x6 0x18da0088 >; /* in zephyr\dts\arm\st\l4\stm32l471.dtsi:283 */
			resets = < &rctl 0x80a >;         /* in zephyr\dts\arm\st\l4\stm32l471.dtsi:285 */
			interrupts = < 0x31 0x0 >;        /* in zephyr\dts\arm\st\l4\stm32l471.dtsi:286 */
			status = "disabled";              /* in zephyr\dts\arm\st\l4\stm32l471.dtsi:287 */
		};

		/* node '/soc/dac@40007400' defined in zephyr\dts\arm\st\l4\stm32l471.dtsi:290 */
		dac1: dac@40007400 {
			compatible = "st,stm32-dac";       /* in zephyr\dts\arm\st\l4\stm32l471.dtsi:291 */
			reg = < 0x40007400 0x400 >;        /* in zephyr\dts\arm\st\l4\stm32l471.dtsi:292 */
			clocks = < &rcc 0x58 0x20000000 >; /* in zephyr\dts\arm\st\l4\stm32l471.dtsi:293 */
			status = "disabled";               /* in zephyr\dts\arm\st\l4\stm32l471.dtsi:294 */
			#io-channel-cells = < 0x1 >;       /* in zephyr\dts\arm\st\l4\stm32l471.dtsi:295 */
		};

		/* node '/soc/adc@50040200' defined in zephyr\dts\arm\st\l4\stm32l471.dtsi:298 */
		adc3: adc@50040200 {
			compatible = "st,stm32-adc";                                /* in zephyr\dts\arm\st\l4\stm32l471.dtsi:299 */
			reg = < 0x50040200 0x100 >;                                 /* in zephyr\dts\arm\st\l4\stm32l471.dtsi:300 */
			clocks = < &rcc 0x4c 0x2000 >;                              /* in zephyr\dts\arm\st\l4\stm32l471.dtsi:301 */
			interrupts = < 0x2f 0x0 >;                                  /* in zephyr\dts\arm\st\l4\stm32l471.dtsi:302 */
			#io-channel-cells = < 0x1 >;                                /* in zephyr\dts\arm\st\l4\stm32l471.dtsi:303 */
			resolutions = < 0x60630c 0x51630c 0x42630c 0x33630c >;      /* in zephyr\dts\arm\st\l4\stm32l471.dtsi:304 */
			sampling-times = < 0x3 0x7 0xd 0x19 0x30 0x5d 0xf8 0x281 >; /* in zephyr\dts\arm\st\l4\stm32l471.dtsi:308 */
			st,adc-sequencer = "programmable";                          /* in zephyr\dts\arm\st\l4\stm32l471.dtsi:309 */
			st,adc-oversampler = "minimal";                             /* in zephyr\dts\arm\st\l4\stm32l471.dtsi:310 */
			st,adc-internal-regulator = "startup-sw-delay";             /* in zephyr\dts\arm\st\l4\stm32l471.dtsi:311 */
			st,adc-has-deep-powerdown;                                  /* in zephyr\dts\arm\st\l4\stm32l471.dtsi:312 */
			st,adc-has-differential-support;                            /* in zephyr\dts\arm\st\l4\stm32l471.dtsi:313 */
			status = "disabled";                                        /* in zephyr\dts\arm\st\l4\stm32l471.dtsi:314 */
		};

		/* node '/soc/otgfs@50000000' defined in zephyr\dts\arm\st\l4\stm32l475.dtsi:13 */
		usbotg_fs: otgfs@50000000 {
			compatible = "st,stm32-otgfs";    /* in zephyr\dts\arm\st\l4\stm32l475.dtsi:14 */
			reg = < 0x50000000 0x40000 >;     /* in zephyr\dts\arm\st\l4\stm32l475.dtsi:15 */
			interrupts = < 0x43 0x0 >;        /* in zephyr\dts\arm\st\l4\stm32l475.dtsi:16 */
			interrupt-names = "otgfs";        /* in zephyr\dts\arm\st\l4\stm32l475.dtsi:17 */
			num-bidir-endpoints = < 0x6 >;    /* in zephyr\dts\arm\st\l4\stm32l475.dtsi:18 */
			ram-size = < 0x500 >;             /* in zephyr\dts\arm\st\l4\stm32l475.dtsi:19 */
			maximum-speed = "full-speed";     /* in zephyr\dts\arm\st\l4\stm32l475.dtsi:20 */
			phys = < &otgfs_phy >;            /* in zephyr\dts\arm\st\l4\stm32l475.dtsi:21 */
			clocks = < &rcc 0x4c 0x1000 >,
			         < &rcc 0x6 0x18da0088 >; /* in zephyr\dts\arm\st\l4\stm32l475.dtsi:22 */
			status = "disabled";              /* in zephyr\dts\arm\st\l4\stm32l475.dtsi:24 */
		};
	};

	/* node '/cpus' defined in zephyr\dts\arm\st\l4\stm32l4.dtsi:31 */
	cpus {
		#address-cells = < 0x1 >; /* in zephyr\dts\arm\st\l4\stm32l4.dtsi:32 */
		#size-cells = < 0x0 >;    /* in zephyr\dts\arm\st\l4\stm32l4.dtsi:33 */

		/* node '/cpus/cpu@0' defined in zephyr\dts\arm\st\l4\stm32l4.dtsi:35 */
		cpu0: cpu@0 {
			device_type = "cpu";                         /* in zephyr\dts\arm\st\l4\stm32l4.dtsi:36 */
			compatible = "arm,cortex-m4f";               /* in zephyr\dts\arm\st\l4\stm32l4.dtsi:37 */
			reg = < 0x0 >;                               /* in zephyr\dts\arm\st\l4\stm32l4.dtsi:38 */
			cpu-power-states = < &stop0 &stop1 &stop2 >; /* in zephyr\dts\arm\st\l4\stm32l4.dtsi:39 */
		};

		/* node '/cpus/power-states' defined in zephyr\dts\arm\st\l4\stm32l4.dtsi:42 */
		power-states {

			/* node '/cpus/power-states/state0' defined in zephyr\dts\arm\st\l4\stm32l4.dtsi:43 */
			stop0: state0 {
				compatible = "zephyr,power-state";    /* in zephyr\dts\arm\st\l4\stm32l4.dtsi:44 */
				power-state-name = "suspend-to-idle"; /* in zephyr\dts\arm\st\l4\stm32l4.dtsi:45 */
				substate-id = < 0x1 >;                /* in zephyr\dts\arm\st\l4\stm32l4.dtsi:46 */
				min-residency-us = < 0x1f4 >;         /* in zephyr\dts\arm\st\l4\stm32l4.dtsi:47 */
				phandle = < 0x11 >;                   /* in zephyr\dts\arm\st\l4\stm32l4.dtsi:39 */
			};

			/* node '/cpus/power-states/state1' defined in zephyr\dts\arm\st\l4\stm32l4.dtsi:50 */
			stop1: state1 {
				compatible = "zephyr,power-state";    /* in zephyr\dts\arm\st\l4\stm32l4.dtsi:51 */
				power-state-name = "suspend-to-idle"; /* in zephyr\dts\arm\st\l4\stm32l4.dtsi:52 */
				substate-id = < 0x2 >;                /* in zephyr\dts\arm\st\l4\stm32l4.dtsi:53 */
				min-residency-us = < 0x2bc >;         /* in zephyr\dts\arm\st\l4\stm32l4.dtsi:54 */
				phandle = < 0x12 >;                   /* in zephyr\dts\arm\st\l4\stm32l4.dtsi:39 */
			};

			/* node '/cpus/power-states/state2' defined in zephyr\dts\arm\st\l4\stm32l4.dtsi:57 */
			stop2: state2 {
				compatible = "zephyr,power-state";    /* in zephyr\dts\arm\st\l4\stm32l4.dtsi:58 */
				power-state-name = "suspend-to-idle"; /* in zephyr\dts\arm\st\l4\stm32l4.dtsi:59 */
				substate-id = < 0x3 >;                /* in zephyr\dts\arm\st\l4\stm32l4.dtsi:60 */
				min-residency-us = < 0x3e8 >;         /* in zephyr\dts\arm\st\l4\stm32l4.dtsi:61 */
				phandle = < 0x13 >;                   /* in zephyr\dts\arm\st\l4\stm32l4.dtsi:39 */
			};
		};
	};

	/* node '/memory@20000000' defined in zephyr\dts\arm\st\l4\stm32l4.dtsi:66 */
	sram0: memory@20000000 {
		compatible = "zephyr,memory-region",
		             "mmio-sram";            /* in zephyr\dts\arm\st\l4\stm32l4.dtsi:67 */
		zephyr,memory-region = "SRAM0";      /* in zephyr\dts\arm\st\l4\stm32l4.dtsi:68 */
		reg = < 0x20000000 0x18000 >;        /* in zephyr\dts\arm\st\l4\stm32l475Xe.dtsi:10 */
	};

	/* node '/clocks' defined in zephyr\dts\arm\st\l4\stm32l4.dtsi:71 */
	clocks {

		/* node '/clocks/clk-hse' defined in zephyr\dts\arm\st\l4\stm32l4.dtsi:72 */
		clk_hse: clk-hse {
			#clock-cells = < 0x0 >;            /* in zephyr\dts\arm\st\l4\stm32l4.dtsi:73 */
			compatible = "st,stm32-hse-clock"; /* in zephyr\dts\arm\st\l4\stm32l4.dtsi:74 */
			status = "disabled";               /* in zephyr\dts\arm\st\l4\stm32l4.dtsi:75 */
		};

		/* node '/clocks/clk-hsi' defined in zephyr\dts\arm\st\l4\stm32l4.dtsi:78 */
		clk_hsi: clk-hsi {
			#clock-cells = < 0x0 >;         /* in zephyr\dts\arm\st\l4\stm32l4.dtsi:79 */
			compatible = "fixed-clock";     /* in zephyr\dts\arm\st\l4\stm32l4.dtsi:80 */
			clock-frequency = < 0xf42400 >; /* in zephyr\dts\arm\st\l4\stm32l4.dtsi:81 */
			status = "okay";                /* in zephyr\boards\alientek\pandora_stm32l475\pandora_stm32l475.dts:105 */
			phandle = < 0x14 >;             /* in zephyr\boards\alientek\pandora_stm32l475\pandora_stm32l475.dts:114 */
		};

		/* node '/clocks/clk-msi' defined in zephyr\dts\arm\st\l4\stm32l4.dtsi:85 */
		clk_msi: clk-msi {
			#clock-cells = < 0x0 >;            /* in zephyr\dts\arm\st\l4\stm32l4.dtsi:86 */
			compatible = "st,stm32-msi-clock"; /* in zephyr\dts\arm\st\l4\stm32l4.dtsi:87 */
			msi-range = < 0x6 >;               /* in zephyr\dts\arm\st\l4\stm32l4.dtsi:88 */
			status = "disabled";               /* in zephyr\dts\arm\st\l4\stm32l4.dtsi:89 */
		};

		/* node '/clocks/clk-lse' defined in zephyr\dts\arm\st\l4\stm32l4.dtsi:92 */
		clk_lse: clk-lse {
			#clock-cells = < 0x0 >;            /* in zephyr\dts\arm\st\l4\stm32l4.dtsi:93 */
			compatible = "st,stm32-lse-clock"; /* in zephyr\dts\arm\st\l4\stm32l4.dtsi:94 */
			clock-frequency = < 0x8000 >;      /* in zephyr\dts\arm\st\l4\stm32l4.dtsi:95 */
			driving-capability = < 0x0 >;      /* in zephyr\dts\arm\st\l4\stm32l4.dtsi:96 */
			status = "disabled";               /* in zephyr\dts\arm\st\l4\stm32l4.dtsi:97 */
		};

		/* node '/clocks/clk-lsi' defined in zephyr\dts\arm\st\l4\stm32l4.dtsi:100 */
		clk_lsi: clk-lsi {
			#clock-cells = < 0x0 >;       /* in zephyr\dts\arm\st\l4\stm32l4.dtsi:101 */
			compatible = "fixed-clock";   /* in zephyr\dts\arm\st\l4\stm32l4.dtsi:102 */
			clock-frequency = < 0x7d00 >; /* in zephyr\dts\arm\st\l4\stm32l4.dtsi:103 */
			status = "okay";              /* in zephyr\boards\alientek\pandora_stm32l475\pandora_stm32l475.dts:101 */
		};

		/* node '/clocks/pll' defined in zephyr\dts\arm\st\l4\stm32l4.dtsi:107 */
		pll: pll {
			#clock-cells = < 0x0 >;              /* in zephyr\dts\arm\st\l4\stm32l4.dtsi:108 */
			compatible = "st,stm32l4-pll-clock"; /* in zephyr\dts\arm\st\l4\stm32l4.dtsi:109 */
			div-m = < 0x1 >;                     /* in zephyr\boards\alientek\pandora_stm32l475\pandora_stm32l475.dts:109 */
			mul-n = < 0x14 >;                    /* in zephyr\boards\alientek\pandora_stm32l475\pandora_stm32l475.dts:110 */
			div-p = < 0x7 >;                     /* in zephyr\boards\alientek\pandora_stm32l475\pandora_stm32l475.dts:111 */
			div-q = < 0x2 >;                     /* in zephyr\boards\alientek\pandora_stm32l475\pandora_stm32l475.dts:112 */
			div-r = < 0x4 >;                     /* in zephyr\boards\alientek\pandora_stm32l475\pandora_stm32l475.dts:113 */
			clocks = < &clk_hsi >;               /* in zephyr\boards\alientek\pandora_stm32l475\pandora_stm32l475.dts:114 */
			status = "okay";                     /* in zephyr\boards\alientek\pandora_stm32l475\pandora_stm32l475.dts:115 */
			phandle = < 0x3 >;                   /* in zephyr\boards\alientek\pandora_stm32l475\pandora_stm32l475.dts:119 */
		};

		/* node '/clocks/pllsai1' defined in zephyr\dts\arm\st\l4\stm32l4.dtsi:113 */
		pllsai1: pllsai1 {
			#clock-cells = < 0x0 >;                 /* in zephyr\dts\arm\st\l4\stm32l4.dtsi:114 */
			compatible = "st,stm32l4-pllsai-clock"; /* in zephyr\dts\arm\st\l4\stm32l4.dtsi:115 */
			status = "disabled";                    /* in zephyr\dts\arm\st\l4\stm32l4.dtsi:116 */
		};

		/* node '/clocks/pllsai2' defined in zephyr\dts\arm\st\l4\stm32l471.dtsi:17 */
		pllsai2: pllsai2 {
			#clock-cells = < 0x0 >;                 /* in zephyr\dts\arm\st\l4\stm32l471.dtsi:18 */
			compatible = "st,stm32l4-pllsai-clock"; /* in zephyr\dts\arm\st\l4\stm32l471.dtsi:19 */
			status = "disabled";                    /* in zephyr\dts\arm\st\l4\stm32l471.dtsi:20 */
		};
	};

	/* node '/mcos' defined in zephyr\dts\arm\st\l4\stm32l4.dtsi:120 */
	mcos {

		/* node '/mcos/mco1' defined in zephyr\dts\arm\st\l4\stm32l4.dtsi:121 */
		mco1: mco1 {
			compatible = "st,stm32-clock-mco"; /* in zephyr\dts\arm\st\l4\stm32l4.dtsi:122 */
			status = "disabled";               /* in zephyr\dts\arm\st\l4\stm32l4.dtsi:123 */
		};
	};

	/* node '/dietemp' defined in zephyr\dts\arm\st\l4\stm32l4.dtsi:551 */
	die_temp: dietemp {
		compatible = "st,stm32-temp-cal"; /* in zephyr\dts\arm\st\l4\stm32l4.dtsi:552 */
		ts-cal1-addr = < 0x1fff75a8 >;    /* in zephyr\dts\arm\st\l4\stm32l4.dtsi:553 */
		ts-cal2-addr = < 0x1fff75ca >;    /* in zephyr\dts\arm\st\l4\stm32l4.dtsi:554 */
		ts-cal1-temp = < 0x1e >;          /* in zephyr\dts\arm\st\l4\stm32l4.dtsi:555 */
		ts-cal-vrefanalog = < 0xbb8 >;    /* in zephyr\dts\arm\st\l4\stm32l4.dtsi:557 */
		io-channels = < &adc1 0x11 >;     /* in zephyr\dts\arm\st\l4\stm32l4.dtsi:558 */
		status = "disabled";              /* in zephyr\dts\arm\st\l4\stm32l4.dtsi:559 */
		ts-cal2-temp = < 0x6e >;          /* in zephyr\dts\arm\st\l4\stm32l471.dtsi:327 */
	};

	/* node '/vref' defined in zephyr\dts\arm\st\l4\stm32l4.dtsi:562 */
	vref: vref {
		compatible = "st,stm32-vref";      /* in zephyr\dts\arm\st\l4\stm32l4.dtsi:563 */
		vrefint-cal-addr = < 0x1fff75aa >; /* in zephyr\dts\arm\st\l4\stm32l4.dtsi:564 */
		vrefint-cal-mv = < 0xbb8 >;        /* in zephyr\dts\arm\st\l4\stm32l4.dtsi:565 */
		io-channels = < &adc1 0x0 >;       /* in zephyr\dts\arm\st\l4\stm32l4.dtsi:566 */
		status = "disabled";               /* in zephyr\dts\arm\st\l4\stm32l4.dtsi:567 */
	};

	/* node '/vbat' defined in zephyr\dts\arm\st\l4\stm32l4.dtsi:570 */
	vbat: vbat {
		compatible = "st,stm32-vbat"; /* in zephyr\dts\arm\st\l4\stm32l4.dtsi:571 */
		ratio = < 0x3 >;              /* in zephyr\dts\arm\st\l4\stm32l4.dtsi:572 */
		io-channels = < &adc1 0x12 >; /* in zephyr\dts\arm\st\l4\stm32l4.dtsi:573 */
		status = "disabled";          /* in zephyr\dts\arm\st\l4\stm32l4.dtsi:574 */
	};

	/* node '/smbus1' defined in zephyr\dts\arm\st\l4\stm32l4.dtsi:577 */
	smbus1: smbus1 {
		compatible = "st,stm32-smbus"; /* in zephyr\dts\arm\st\l4\stm32l4.dtsi:578 */
		#address-cells = < 0x1 >;      /* in zephyr\dts\arm\st\l4\stm32l4.dtsi:579 */
		#size-cells = < 0x0 >;         /* in zephyr\dts\arm\st\l4\stm32l4.dtsi:580 */
		i2c = < &i2c1 >;               /* in zephyr\dts\arm\st\l4\stm32l4.dtsi:581 */
		status = "disabled";           /* in zephyr\dts\arm\st\l4\stm32l4.dtsi:582 */
	};

	/* node '/smbus3' defined in zephyr\dts\arm\st\l4\stm32l4.dtsi:585 */
	smbus3: smbus3 {
		compatible = "st,stm32-smbus"; /* in zephyr\dts\arm\st\l4\stm32l4.dtsi:586 */
		#address-cells = < 0x1 >;      /* in zephyr\dts\arm\st\l4\stm32l4.dtsi:587 */
		#size-cells = < 0x0 >;         /* in zephyr\dts\arm\st\l4\stm32l4.dtsi:588 */
		i2c = < &i2c3 >;               /* in zephyr\dts\arm\st\l4\stm32l4.dtsi:589 */
		status = "disabled";           /* in zephyr\dts\arm\st\l4\stm32l4.dtsi:590 */
	};

	/* node '/sai1@40015404' defined in zephyr\dts\arm\st\l4\stm32l4.dtsi:593 */
	sai1_a: sai1@40015404 {
		compatible = "st,stm32-sai";      /* in zephyr\dts\arm\st\l4\stm32l4.dtsi:594 */
		#address-cells = < 0x1 >;         /* in zephyr\dts\arm\st\l4\stm32l4.dtsi:595 */
		#size-cells = < 0x0 >;            /* in zephyr\dts\arm\st\l4\stm32l4.dtsi:596 */
		reg = < 0x40015404 0x20 >;        /* in zephyr\dts\arm\st\l4\stm32l4.dtsi:597 */
		clocks = < &rcc 0x60 0x200000 >,
		         < &rcc 0xd 0xd60088 >;   /* in zephyr\dts\arm\st\l4\stm32l4.dtsi:598 */
		dmas = < &dma2 0x1 0x1 0x22800 >; /* in zephyr\dts\arm\st\l4\stm32l4.dtsi:600 */
		status = "disabled";              /* in zephyr\dts\arm\st\l4\stm32l4.dtsi:602 */
	};

	/* node '/sai1@40015424' defined in zephyr\dts\arm\st\l4\stm32l4.dtsi:605 */
	sai1_b: sai1@40015424 {
		compatible = "st,stm32-sai";      /* in zephyr\dts\arm\st\l4\stm32l4.dtsi:606 */
		#address-cells = < 0x1 >;         /* in zephyr\dts\arm\st\l4\stm32l4.dtsi:607 */
		#size-cells = < 0x0 >;            /* in zephyr\dts\arm\st\l4\stm32l4.dtsi:608 */
		reg = < 0x40015424 0x20 >;        /* in zephyr\dts\arm\st\l4\stm32l4.dtsi:609 */
		clocks = < &rcc 0x60 0x200000 >,
		         < &rcc 0xd 0xd60088 >;   /* in zephyr\dts\arm\st\l4\stm32l4.dtsi:610 */
		dmas = < &dma2 0x2 0x1 0x22800 >; /* in zephyr\dts\arm\st\l4\stm32l4.dtsi:612 */
		status = "disabled";              /* in zephyr\dts\arm\st\l4\stm32l4.dtsi:614 */
	};

	/* node '/memory@10000000' defined in zephyr\dts\arm\st\l4\stm32l471.dtsi:11 */
	sram1: memory@10000000 {
		compatible = "zephyr,memory-region",
		             "mmio-sram";            /* in zephyr\dts\arm\st\l4\stm32l471.dtsi:12 */
		zephyr,memory-region = "SRAM1";      /* in zephyr\dts\arm\st\l4\stm32l471.dtsi:13 */
		reg = < 0x10000000 0x8000 >;         /* in zephyr\dts\arm\st\l4\stm32l475Xe.dtsi:14 */
	};

	/* node '/smbus2' defined in zephyr\dts\arm\st\l4\stm32l471.dtsi:330 */
	smbus2: smbus2 {
		compatible = "st,stm32-smbus"; /* in zephyr\dts\arm\st\l4\stm32l471.dtsi:331 */
		#address-cells = < 0x1 >;      /* in zephyr\dts\arm\st\l4\stm32l471.dtsi:332 */
		#size-cells = < 0x0 >;         /* in zephyr\dts\arm\st\l4\stm32l471.dtsi:333 */
		i2c = < &i2c2 >;               /* in zephyr\dts\arm\st\l4\stm32l471.dtsi:334 */
		status = "disabled";           /* in zephyr\dts\arm\st\l4\stm32l471.dtsi:335 */
	};

	/* node '/otgfs_phy' defined in zephyr\dts\arm\st\l4\stm32l475.dtsi:28 */
	otgfs_phy: otgfs_phy {
		compatible = "usb-nop-xceiv"; /* in zephyr\dts\arm\st\l4\stm32l475.dtsi:29 */
		#phy-cells = < 0x0 >;         /* in zephyr\dts\arm\st\l4\stm32l475.dtsi:30 */
		phandle = < 0x10 >;           /* in zephyr\dts\arm\st\l4\stm32l475.dtsi:21 */
	};

	/* node '/leds' defined in zephyr\boards\alientek\pandora_stm32l475\pandora_stm32l475.dts:32 */
	leds {
		compatible = "gpio-leds"; /* in application\pandora_stm32l475.overlay:20 */

		/* node '/leds/led_0' defined in zephyr\boards\alientek\pandora_stm32l475\pandora_stm32l475.dts:35 */
		red_led: led_0 {
			label = "User LED_R";       /* in zephyr\boards\alientek\pandora_stm32l475\pandora_stm32l475.dts:37 */
			gpios = < &gpioe 0x7 0x1 >; /* in application\pandora_stm32l475.overlay:30 */
		};

		/* node '/leds/led_1' defined in zephyr\boards\alientek\pandora_stm32l475\pandora_stm32l475.dts:40 */
		green_led: led_1 {
			label = "User LED_G";       /* in zephyr\boards\alientek\pandora_stm32l475\pandora_stm32l475.dts:42 */
			gpios = < &gpioe 0x8 0x1 >; /* in application\pandora_stm32l475.overlay:34 */
		};

		/* node '/leds/led_2' defined in zephyr\boards\alientek\pandora_stm32l475\pandora_stm32l475.dts:45 */
		blue_led: led_2 {
			label = "User LED_B";       /* in zephyr\boards\alientek\pandora_stm32l475\pandora_stm32l475.dts:47 */
			gpios = < &gpioe 0x9 0x1 >; /* in application\pandora_stm32l475.overlay:38 */
		};
	};

	/* node '/gpio_keys' defined in zephyr\boards\alientek\pandora_stm32l475\pandora_stm32l475.dts:51 */
	gpio_keys {
		compatible = "gpio-keys"; /* in zephyr\boards\alientek\pandora_stm32l475\pandora_stm32l475.dts:52 */

		/* node '/gpio_keys/joystick_up' defined in zephyr\boards\alientek\pandora_stm32l475\pandora_stm32l475.dts:54 */
		joy_up: joystick_up {
			label = "joystick up";       /* in zephyr\boards\alientek\pandora_stm32l475\pandora_stm32l475.dts:55 */
			gpios = < &gpioc 0xd 0x20 >; /* in zephyr\boards\alientek\pandora_stm32l475\pandora_stm32l475.dts:56 */
			zephyr,code = < 0x67 >;      /* in zephyr\boards\alientek\pandora_stm32l475\pandora_stm32l475.dts:57 */
		};

		/* node '/gpio_keys/joystick_down' defined in zephyr\boards\alientek\pandora_stm32l475\pandora_stm32l475.dts:60 */
		joy_down: joystick_down {
			label = "joystick down";     /* in zephyr\boards\alientek\pandora_stm32l475\pandora_stm32l475.dts:61 */
			gpios = < &gpiod 0x9 0x11 >; /* in zephyr\boards\alientek\pandora_stm32l475\pandora_stm32l475.dts:62 */
			zephyr,code = < 0x6c >;      /* in zephyr\boards\alientek\pandora_stm32l475\pandora_stm32l475.dts:63 */
		};

		/* node '/gpio_keys/joystick_left' defined in zephyr\boards\alientek\pandora_stm32l475\pandora_stm32l475.dts:66 */
		joy_left: joystick_left {
			label = "joystick left";     /* in zephyr\boards\alientek\pandora_stm32l475\pandora_stm32l475.dts:67 */
			gpios = < &gpiod 0x8 0x11 >; /* in zephyr\boards\alientek\pandora_stm32l475\pandora_stm32l475.dts:68 */
			zephyr,code = < 0x69 >;      /* in zephyr\boards\alientek\pandora_stm32l475\pandora_stm32l475.dts:69 */
		};

		/* node '/gpio_keys/joystick_right' defined in zephyr\boards\alientek\pandora_stm32l475\pandora_stm32l475.dts:72 */
		joy_right: joystick_right {
			label = "joystick right";    /* in zephyr\boards\alientek\pandora_stm32l475\pandora_stm32l475.dts:73 */
			gpios = < &gpiod 0xa 0x11 >; /* in zephyr\boards\alientek\pandora_stm32l475\pandora_stm32l475.dts:74 */
			zephyr,code = < 0x6a >;      /* in zephyr\boards\alientek\pandora_stm32l475\pandora_stm32l475.dts:75 */
		};
	};

	/* node '/pwmleds' defined in application\pandora_stm32l475.overlay:4 */
	pwmleds: pwmleds {
		compatible = "pwm-leds"; /* in application\pandora_stm32l475.overlay:5 */
		status = "okay";         /* in application\pandora_stm32l475.overlay:6 */

		/* node '/pwmleds/green_pwm_led' defined in application\pandora_stm32l475.overlay:8 */
		green_pwm_led: green_pwm_led {
			pwms = < &pwm4 0x1 0x1312d00 0x0 >; /* in application\pandora_stm32l475.overlay:9 */
		};
	};
};
